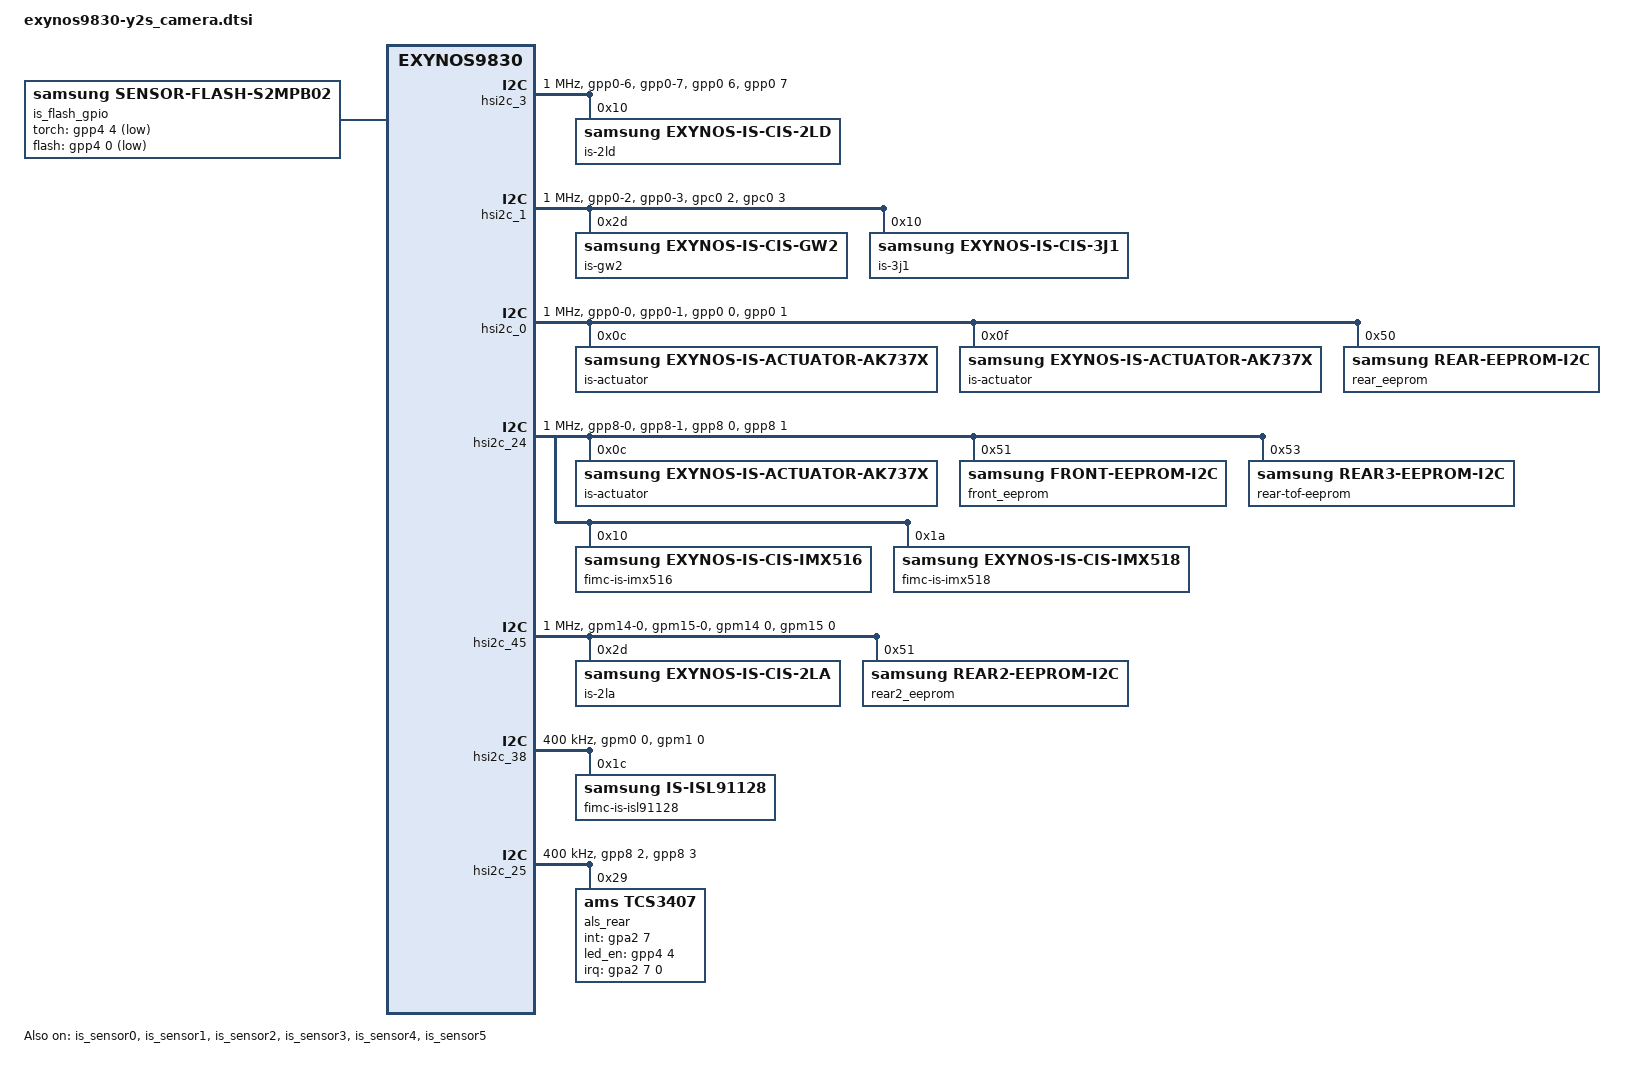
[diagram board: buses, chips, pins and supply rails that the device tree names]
/*
 * Samsung Exynos SoC series Pablo driver
 *
 * Copyright (c) 2019 Samsung Electronics Co., Ltd
 *
 * This program is free software; you can redistribute it and/or modify
 * it under the terms of the GNU General Public License version 2 as
 * published by the Free Software Foundation.
 */

#include <dt-bindings/camera/exynos_is_dt.h>
#include <dt-bindings/interrupt-controller/exynos9830.h>
#include <dt-bindings/clock/exynos9830.h>

#include "camera/module_2ld.dtsi"
#include "camera/module_3j1.dtsi"
#include "camera/module_2la.dtsi"
#include "camera/module_gw2.dtsi"
#include "camera/module_imx516.dtsi"
#include "camera/module_imx518.dtsi"

/ {
	fragment@camera {
		target-path = "/";
		__overlay__ {
			/* REAR CAMERA */
			is_sensor_2ld: is_sensor_2ld@20 {
				pinctrl-names = "pin0", "pin1", "pin2", "release";
				pinctrl-0 = <>;
				pinctrl-1 = <&sensor_mclk0_out>;
				pinctrl-2 = <&sensor_mclk0_fn>;
				pinctrl-3 = <>;

				/* board */
				position = <0>;	/* Rear:0. Front:1. Rear_sub:2. Secure:3. */
				id = <0>; /* is_sensor id */
				mclk_ch = <0>;
				sensor_i2c_ch = <0>; /* SENSOR_CONTROL_I2C0 */

				/* vendor */
				rom_type = <2>; /* ROM_TYPE_EEPROM */
				rom_id = <0>;
				rom_cal_index = <0>;

				/* peri */
				af {
					product_name = <18>; /* ACTUATOR_NAME_AK737X : ak7371 or ak7374 */
					i2c_ch = <2>; /* SENSOR_CONTROL_I2C2 */
				};

				flash {
					product_name = <11>; /* FLASH_GPIO */
				};

				mcu {
					product_name = <2>; /* INTERNAL */
				};

				vc_extra {
					/* ex) statX = <stat_type, sensor_mode, max_width, max_height, max_element> */
					stat0 = </* not avaliable */>;									/* VC_BUF_DATA_TYPE_SENSOR_STAT1 */
					stat1 = </*VC_STAT_TYPE_PDP_1_1_PDAF_STAT0*/ 800 /*VC_SENSOR_MODE_2PD_MODE3*/ 102 512 84 1>;	/* VC_BUF_DATA_TYPE_GENERAL_STAT1 */
					stat2 = </* not avaliable */>;									/* VC_BUF_DATA_TYPE_SENSOR_STAT2 */
					stat3 = </*VC_STAT_TYPE_PDP_1_1_PDAF_STAT1*/ 801 /*VC_SENSOR_MODE_2PD_MODE3*/ 102 512 84 1>;	/* VC_BUF_DATA_TYPE_GENERAL_STAT2 */
				};

				modes { 
					/* common = <width, height, fps, settle, mode, lane, speed, interleave, lrte, pd_mode> */
					/* vcX = <map, hwformat, width, height, hwformat, type, width, height> */
					/* CAMERA_2LD_SLOW_MOTION_PDAF_OFF */
					mode9 { /* SENSOR_2LD_2016X1134_240FPS */
						common = <2016 1134 240 0 9 CSI_DATA_LANES_3 2964 CSI_MODE_VC_DT LRTE_ENABLE PD_NONE>;
						vc1 = </* in */ 1 HW_FORMAT_UNKNOWN 0 0	/* out */ HW_FORMAT_UNKNOWN VC_NOTHING 0 0>;
					};
				};

				power_seq {
					use = <1>;
					gpio_mclk = <&gpc0 0 0x1>;

					scenario_normal_on {
						sensor_scenario = <SENSOR_SCENARIO_NORMAL>;
						gpio_scenario = <GPIO_SCENARIO_ON>;

						/* A start node number should be over the 10 for reserved number 0~9. */
						/* pname = "name"; pin = <act value delay voltage>; gpio = <gpx# # 0x1>; */
						5 { pname = "S2MPB02_BUCK2"; pin = <PIN_REGULATOR 1 0>; share = <SRT_ACQUIRE SHARED_PIN5 1>; };
						20 { pname = "VDDIO_1.8V_CAM"; pin = <PIN_REGULATOR 1 300>; share = <SRT_ACQUIRE SHARED_PIN2 1>; };
						60 { pname = "VDDAF_COMMON_CAM"; pin = <PIN_REGULATOR 1 1>; actuator_i2c_delay = <10000>; };
						85 { pname = "VDD_VM_2.8V_OIS"; pin = <PIN_REGULATOR 1 100>; share = <SRT_ACQUIRE SHARED_PIN3 1>; };
						86 { pname = "VDDD_1.8V_OIS"; pin = <PIN_REGULATOR 1 0>; share = <SRT_ACQUIRE SHARED_PIN4 1>; };
						100 { pname = "pin"; pin = <PIN_FUNCTION 2 0>; share = <SRT_ACQUIRE SHARED_PIN1 1>; };
						110 { pname = "MCLK"; pin = <PIN_MCLK 1 1500>; share = <SRT_ACQUIRE SHARED_PIN0 1>; };
					};

					scenario_vision_on {
					};

					scenario_hw_init_normal_on {
						/* HW INIT (without ois power control) */
					};

					scenario_normal_off {
						sensor_scenario = <SENSOR_SCENARIO_NORMAL>;
						gpio_scenario = <GPIO_SCENARIO_OFF>;

						/* A start node number should be over the 10 for reserved number 0~9. */
						/* pname = "name"; pin = <act value delay voltage>; gpio = <gpx# # 0x1>; */
						60 { pname = "MCLK"; pin = <PIN_MCLK 0 0>; share = <SRT_RELEASE SHARED_PIN0 0>; };
						80 { pname = "pin"; pin = <PIN_FUNCTION 1 0>; share = <SRT_RELEASE SHARED_PIN1 0>; };
						116 { pname = "VDDD_1.8V_OIS"; pin = <PIN_REGULATOR 0 0>; share = <SRT_RELEASE SHARED_PIN4 0>; };
						117 { pname = "VDD_VM_2.8V_OIS"; pin = <PIN_REGULATOR 0 0>; share = <SRT_RELEASE SHARED_PIN3 0>; };
						130 { pname = "VDDIO_1.8V_CAM"; pin = <PIN_REGULATOR 0 10>; share = <SRT_RELEASE SHARED_PIN2 0>; };
						140 { pname = "S2MPB02_BUCK2"; pin = <PIN_REGULATOR 0 0>; share = <SRT_RELEASE SHARED_PIN5 0>; };
					};

					scenario_vision_off {
					};

					scenario_retention_on {
						sensor_scenario = <SENSOR_SCENARIO_NORMAL>;
						gpio_scenario = <GPIO_SCENARIO_SENSOR_RETENTION_ON>;

						/* A start node number should be over the 10 for reserved number 0~9. */
						/* pname = "name"; pin = <act value delay voltage>; gpio = <gpx# # 0x1>; */
						20 { pname = "MCLK"; pin = <PIN_MCLK 0 0>; share = <SRT_RELEASE SHARED_PIN0 0>; };
						40 { pname = "pin"; pin = <PIN_FUNCTION 1 0>; share = <SRT_RELEASE SHARED_PIN1 0>; };
						116 { pname = "VDD_VM_2.8V_OIS"; pin = <PIN_REGULATOR 0 0>; share = <SRT_RELEASE SHARED_PIN3 0>; };
						117 { pname = "VDDD_1.8V_OIS"; pin = <PIN_REGULATOR 0 0>; share = <SRT_RELEASE SHARED_PIN4 0>; };
						140 { pname = "S2MPB02_BUCK2"; pin = <PIN_REGULATOR 0 0>; share = <SRT_RELEASE SHARED_PIN5 0>; };
					};

					scenario_hw_init_retention_on {
						/* RETENTION ON HW INIT(without ois power control) */
					};

					scenario_ois_factory_on {
					};

					scenario_ois_factory_off {
					};

					scenario_read_rom_on {
					};

					scenario_read_rom_off {
					};
				};
			};

			/* Tele CAMERA */
			is_sensor_gw2: is_sensor_gw2@5A {
				pinctrl-names = "pin0", "pin1", "pin2", "release";
				pinctrl-0 = <>;
				pinctrl-1 = <&sensor_mclk0_out>;
				pinctrl-2 = <&sensor_mclk0_fn>;
				pinctrl-3 = <>;

				/* board */
				position = <2>; /* Rear:0. Front:1, Tele:2 */
				id = <2>; /* is_sensor id */
				mclk_ch = <0>;
				sensor_i2c_ch = <1>; /* SENSOR_CONTROL_I2C1 */

				/* vendor */
				rom_type = <2>; /* ROM_TYPE_EEPROM */
				rom_id = <0>;
				rom_cal_index = <1>;
				rom_dualcal_id = <0>;
				rom_dualcal_index = <1>;

				af {
					product_name = <18>; /* ACTUATOR_NAME_AK737X : ak7371 or ak7374 */
					i2c_ch = <2>; /* SENSOR_CONTROL_I2C2 */
				};

				flash {
					product_name = <11>; /* FLASH_GPIO */
				};

				preprocessor {
					product_name = <100>; /* NOTHING */
				};

				mcu {
					product_name = <2>; /* INTERNAL */
				};

				vc_extra {
					/* ex) statX = <stat_type, sensor_mode, max_width, max_height, max_element> */
					stat0 = </* not avaliable */>;			/* VC_BUF_DATA_TYPE_SENSOR_STAT1 */
					stat1 = </*VC_STAT_TYPE_PDP_1_1_PDAF_STAT0*/ 800 /*VC_SENSOR_MODE_2PD_MODE3*/ 405 1160 1736 2>;		/* VC_BUF_DATA_TYPE_GENERAL_STAT1 */
					stat2 = </* not avaliable */>;			/* VC_BUF_DATA_TYPE_SENSOR_STAT2 */
					stat3 = </*VC_STAT_TYPE_PDP_1_1_PDAF_STAT1*/ 801 /*VC_SENSOR_MODE_2PD_MODE3*/ 405 1160 1736 2>;	/* VC_BUF_DATA_TYPE_GENERAL_STAT2 */
				};

				power_seq {
					use = <1>;
					gpio_mclk = <&gpc0 0 0x1>;

					scenario_normal_on {
						sensor_scenario = <SENSOR_SCENARIO_NORMAL>;
						gpio_scenario = <GPIO_SCENARIO_ON>;

						/* A start node number should be over the 10 for reserved number 0~9. */
						/* pname = "name"; pin = <act value delay voltage>; gpio = <gpx# # 0x1>; */
						30 { pname = "VDDAF_2.8V_SUB"; pin = <PIN_REGULATOR 1 2000>; actuator_i2c_delay = <10000>; };
						35 { pname = "VDD_VM_2.8V_OIS"; pin = <PIN_REGULATOR 1 100>; share = <SRT_ACQUIRE SHARED_PIN3 1>; };
						36 { pname = "VDDD_1.8V_OIS"; pin = <PIN_REGULATOR 1 0>; share = <SRT_ACQUIRE SHARED_PIN4 1>; };
						40 { pname = "VDDIO_1.8V_CAM"; pin = <PIN_REGULATOR 1 100>; share = <SRT_ACQUIRE SHARED_PIN2 1>; };
						45 { pname = "VDDIO_1.8V_VT"; pin = <PIN_REGULATOR 1 0>; share = <SRT_ACQUIRE SHARED_PIN6 1>; };
						70 { pname = "pin"; pin = <PIN_FUNCTION 2 0>; share = <SRT_ACQUIRE SHARED_PIN1 1>; };
						80 { pname = "MCLK"; pin = <PIN_MCLK 1 0>; share = <SRT_ACQUIRE SHARED_PIN0 1>; };
					};

					scenario_normal_off {
						sensor_scenario = <SENSOR_SCENARIO_NORMAL>;
						gpio_scenario = <GPIO_SCENARIO_OFF>;

						/* A start node number should be over the 10 for reserved number 0~9. */
						/* pname = "name"; pin = <act value delay voltage>; gpio = <gpx# # 0x1>; */
						40 { pname = "VDDIO_1.8V_CAM"; pin = <PIN_REGULATOR 0 0>; share = <SRT_RELEASE SHARED_PIN2 0>; };
						55 { pname = "VDDIO_1.8V_VT"; pin = <PIN_REGULATOR 0 0>; share = <SRT_RELEASE SHARED_PIN6 0>; };
						76 { pname = "VDDD_1.8V_OIS"; pin = <PIN_REGULATOR 0 0>; share = <SRT_RELEASE SHARED_PIN4 0>; };
						77 { pname = "VDD_VM_2.8V_OIS"; pin = <PIN_REGULATOR 0 0>; share = <SRT_RELEASE SHARED_PIN3 0>; };
						80 { pname = "MCLK"; pin = <PIN_MCLK 0 0>; share = <SRT_RELEASE SHARED_PIN0 0>; };
						100 { pname = "pin"; pin = <PIN_FUNCTION 1 0>; share = <SRT_RELEASE SHARED_PIN1 0>; };
					};

					scenario_vision_on {
					};

					scenario_vision_off {
					};
				};
			};

			/* Ultra Wide CAMERA */
			is_sensor_2la: is_sensor_2la@2D {
				pinctrl-names = "pin0", "pin1", "pin2", "release";
				pinctrl-0 = <>;
				pinctrl-1 = <&sensor_mclk4_out>;
				pinctrl-2 = <&sensor_mclk4_fn>;
				pinctrl-3 = <>;

				/* board */
				position = <4>; /* Rear:0. Front:1, Tele:2 */
				id = <4>; /* is_sensor id */
				mclk_ch = <3>;
				sensor_i2c_ch = <4>; /* SENSOR_CONTROL_I2C4 */

				/* vendor */
				rom_type = <2>; /* ROM_TYPE_EEPROM */
				rom_id = <2>;
				rom_cal_index = <0>;
				rom_dualcal_id = <0>;
				rom_dualcal_index = <0>;

				af {
					product_name = <100>; /* NOTHING */
				};

				flash {
					product_name = <11>; /* FLASH_GPIO */
				};

				preprocessor {
					product_name = <100>; /* NOTHING */
				};

				ois {
					product_name = <100>; /* NOTHING */
				};

				power_seq {
					use = <1>;
					gpio_mclk = <&gpc0 3 0x1>;

					scenario_normal_on {
						sensor_scenario = <SENSOR_SCENARIO_NORMAL>;
						gpio_scenario = <GPIO_SCENARIO_ON>;

						/* A start node number should be over the 10 for reserved number 0~9. */
						/* pname = "name"; pin = <act value delay voltage>; gpio = <gpx# # 0x1>; */
						5 { pname = "S2MPB02_BUCK2"; pin = <PIN_REGULATOR 1 0>; share = <SRT_ACQUIRE SHARED_PIN5 1>; };
					};

					scenario_normal_off {
						sensor_scenario = <SENSOR_SCENARIO_NORMAL>;
						gpio_scenario = <GPIO_SCENARIO_OFF>;

						/* A start node number should be over the 10 for reserved number 0~9. */
						/* pname = "name"; pin = <act value delay voltage>; gpio = <gpx# # 0x1>; */
						140 { pname = "S2MPB02_BUCK2"; pin = <PIN_REGULATOR 0 0>; share = <SRT_RELEASE SHARED_PIN5 0>; };
					};

					scenario_vision_on {
					};

					scenario_vision_off {
					};

					scenario_read_rom_on {
					};

					scenario_read_rom_off {
					};
				};
			};

			/* FRONT CAMERA */
			is_sensor_3j1: is_sensor_3j1@10 {
				pinctrl-names = "pin0", "pin1", "pin2", "release";
				pinctrl-0 = <>;
				pinctrl-1 = <&sensor_mclk2_out>;
				pinctrl-2 = <&sensor_mclk2_fn>;
				pinctrl-3 = <>;

				/* board */
				position = <1>;	/* Rear:0. Front:1. Rear_sub:2. Secure:3. */
				id = <1>; /* is_sensor id */
				mclk_ch = <1>;
				sensor_i2c_ch = <1>; /* SENSOR_CONTROL_I2C1 */

				/* vendor */
				rom_type = <2>; /* ROM_TYPE_EEPROM */
				rom_id = <1>;
				rom_cal_index = <0>;

				/* peri*/
				af {
					product_name = <18>; /* ACTUATOR_NAME_AK737X */
					i2c_ch = <3>; /* SENSOR_CONTROL_I2C3 */
				};

				flash {
					product_name = <100>; /* NOTHING */
				};

				ois {
					product_name = <100>; /* NOTHING */
				};

				vc_extra {
					/* ex) statX = <stat_type, sensor_mode, max_width, max_height, max_element> */
					stat0 = </* not avaliable */>;									/* VC_BUF_DATA_TYPE_SENSOR_STAT1 */
					stat1 = </*VC_STAT_TYPE_PDP_1_1_PDAF_STAT0*/ 800 /*VC_SENSOR_MODE_2PD_MODE3*/ 102 512 84 1>;	/* VC_BUF_DATA_TYPE_GENERAL_STAT1 */
					stat2 = </* not avaliable */>;									/* VC_BUF_DATA_TYPE_SENSOR_STAT2 */
					stat3 = </*VC_STAT_TYPE_PDP_1_1_PDAF_STAT1*/ 801 /*VC_SENSOR_MODE_2PD_MODE3*/ 102 512 84 1>;	/* VC_BUF_DATA_TYPE_GENERAL_STAT2 */
				};

				power_seq {
					use = <1>;
					gpio_mclk = <&gpc0 1 0x1>;

					scenario_normal_on {
						sensor_scenario = <SENSOR_SCENARIO_NORMAL>;
						gpio_scenario = <GPIO_SCENARIO_ON>;

						/* A start node number should be over the 10 for reserved number 0~9. */
						/* pname = "name"; pin = <act value delay voltage>; gpio = <gpx# # 0x1>; */
						5 { pname = "S2MPB02_BUCK2"; pin = <PIN_REGULATOR 1 0>; share = <SRT_ACQUIRE SHARED_PIN5 1>; };
						10 { pname = "VDDAF_2.8V_VT"; pin = <PIN_REGULATOR 1 0>; actuator_i2c_delay = <10000>; };
						70 { pname = "pin"; pin = <PIN_FUNCTION 2 0>; };
						80 { pname = "MCLK"; pin = <PIN_MCLK 1 9000>; };
					};

					scenario_normal_off {
						sensor_scenario = <SENSOR_SCENARIO_NORMAL>;
						gpio_scenario = <GPIO_SCENARIO_OFF>;

						/* A start node number should be over the 10 for reserved number 0~9. */
						/* pname = "name"; pin = <act value delay voltage>; gpio = <gpx# # 0x1>; */
						10 { pname = "MCLK"; pin = <PIN_MCLK 0 1>; };
						30 { pname = "pin"; pin = <PIN_FUNCTION 1 0>; };
						140 { pname = "S2MPB02_BUCK2"; pin = <PIN_REGULATOR 0 0>; share = <SRT_RELEASE SHARED_PIN5 0>; };
					};

					scenario_vision_on {
					};

					scenario_vision_off {
					};
				};
			};

			/* REAR TOF */
			is_sensor_imx516: is_sensor_imx516@10 {
				pinctrl-names = "pin0", "pin1", "pin2", "release";
				pinctrl-0 = <>;
				pinctrl-1 = <&sensor_mclk3_out>;
				pinctrl-2 = <&sensor_mclk3_fn>;
				pinctrl-3 = <>;

				position = <8>; /* Rear:0. Front:1, Tele:2 */
				id = <3>; /* fimc_is_sensor id */
				mclk_ch = <2>;
				sensor_i2c_ch = <3>; /* SENSOR_CONTROL_I2C3 */

				rom_type = <2>; /* ROM_TYPE_EEPROM */
				rom_id = <4>;
				rom_cal_index = <0>;
				rom_dualcal_id = <0>;
				rom_dualcal_index = <2>;

				af {
					product_name = <100>;  /* NOTHING */
				};

				flash {
					product_name = <100>;  /* NOTHING */
				};

				preprocessor {
					product_name = <100>; /* NOTHING */
				};

				ois {
					product_name = <100>; /* NOTHING */
				};

				power_seq {
					use = <1>;
					gpio_mclk = <&gpc0 2 0x1>;

					scenario_normal_on {
						sensor_scenario = <SENSOR_SCENARIO_VISION>;
						gpio_scenario = <GPIO_SCENARIO_ON>;

						/* A start node number should be over the 10 for reserved number 0~9. */
						/* pname = "name"; pin = <act value dealy voltage>; gpio = <gpx# # 0x1>; */
						5 { pname = "S2MPB02_BUCK2"; pin = <PIN_REGULATOR 1 0>; share = <SRT_ACQUIRE SHARED_PIN5 1>; };
						45 { pname = "VDDIO_1.8V_VT"; pin = <PIN_REGULATOR 1 0>; share = <SRT_ACQUIRE SHARED_PIN6 1>; };
					};

					scenario_normal_off {
						sensor_scenario = <SENSOR_SCENARIO_VISION>;
						gpio_scenario = <GPIO_SCENARIO_OFF>;

						/* A start node number should be over the 10 for reserved number 0~9. */
						/* pname = "name"; pin = <act value dealy voltage>; gpio = <gpx# # 0x1>; */
						15 { pname = "VDDIO_1.8V_VT"; pin = <PIN_REGULATOR 0 0>; share = <SRT_RELEASE SHARED_PIN6 0>; };
						140 { pname = "S2MPB02_BUCK2"; pin = <PIN_REGULATOR 0 0>; share = <SRT_RELEASE SHARED_PIN5 0>; };
					};

					scenario_read_rom_on {
						sensor_scenario = <SENSOR_SCENARIO_READ_ROM>;
						gpio_scenario = <GPIO_SCENARIO_ON>;

						/* A start node number should be over the 10 for reserved number 0~9. */
						/* pname = "name"; pin = <act value dealy voltage>; gpio = <gpx# # 0x1>; */
						15 { pname = "VDDIO_1.8V_VT"; pin = <PIN_REGULATOR 1 0>; share = <SRT_ACQUIRE SHARED_PIN6 1>; };
					};

					scenario_read_rom_off {
						sensor_scenario = <SENSOR_SCENARIO_READ_ROM>;
						gpio_scenario = <GPIO_SCENARIO_OFF>;

						/* A start node number should be over the 10 for reserved number 0~9. */
						/* pname = "name"; pin = <act value dealy voltage>; gpio = <gpx# # 0x1>; */
						15 { pname = "VDDIO_1.8V_VT"; pin = <PIN_REGULATOR 0 0>; share = <SRT_RELEASE SHARED_PIN6 0>; };
					};
				};
			};

			is_sensor_imx518: is_sensor_imx518@1A {
				pinctrl-names = "pin0", "pin1", "pin2", "release";
				pinctrl-0 = <>;
				pinctrl-1 = <&sensor_mclk3_out>;
				pinctrl-2 = <&sensor_mclk3_fn>;
				pinctrl-3 = <>;

				position = <8>; /* Rear:0. Front:1, Tele:2 */
				id = <3>; /* fimc_is_sensor id */
				mclk_ch = <2>;
				sensor_i2c_ch = <3>; /* SENSOR_CONTROL_I2C3 */

				rom_type = <2>; /* ROM_TYPE_EEPROM */
				rom_id = <4>;
				rom_cal_index = <0>;
				rom_dualcal_id = <0>;
				rom_dualcal_index = <2>;

				af {
					product_name = <100>;  /* NOTHING */
				};

				flash {
					product_name = <100>;  /* NOTHING */
				};

				preprocessor {
					product_name = <100>; /* NOTHING */
				};

				ois {
					product_name = <100>; /* NOTHING */
				};

				power_seq {
					use = <1>;
					gpio_mclk = <&gpc0 2 0x1>;

					scenario_normal_on {
						sensor_scenario = <SENSOR_SCENARIO_VISION>;
						gpio_scenario = <GPIO_SCENARIO_ON>;

						/* A start node number should be over the 10 for reserved number 0~9. */
						/* pname = "name"; pin = <act value dealy voltage>; gpio = <gpx# # 0x1>; */
						5 { pname = "S2MPB02_BUCK2"; pin = <PIN_REGULATOR 1 0>; share = <SRT_ACQUIRE SHARED_PIN5 1>; };
						45 { pname = "VDDIO_1.8V_VT"; pin = <PIN_REGULATOR 1 0>; share = <SRT_ACQUIRE SHARED_PIN6 1>; };
					};

					scenario_normal_off {
						sensor_scenario = <SENSOR_SCENARIO_VISION>;
						gpio_scenario = <GPIO_SCENARIO_OFF>;

						/* A start node number should be over the 10 for reserved number 0~9. */
						/* pname = "name"; pin = <act value dealy voltage>; gpio = <gpx# # 0x1>; */
						15 { pname = "VDDIO_1.8V_VT"; pin = <PIN_REGULATOR 0 0>; share = <SRT_RELEASE SHARED_PIN6 0>; };
						140 { pname = "S2MPB02_BUCK2"; pin = <PIN_REGULATOR 0 0>; share = <SRT_RELEASE SHARED_PIN5 0>; };
					};

					scenario_read_rom_on {
						sensor_scenario = <SENSOR_SCENARIO_READ_ROM>;
						gpio_scenario = <GPIO_SCENARIO_ON>;

						/* A start node number should be over the 10 for reserved number 0~9. */
						/* pname = "name"; pin = <act value dealy voltage>; gpio = <gpx# # 0x1>; */
						15 { pname = "VDDIO_1.8V_VT"; pin = <PIN_REGULATOR 1 0>; share = <SRT_ACQUIRE SHARED_PIN6 1>; };
					};

					scenario_read_rom_off {
						sensor_scenario = <SENSOR_SCENARIO_READ_ROM>;
						gpio_scenario = <GPIO_SCENARIO_OFF>;

						/* A start node number should be over the 10 for reserved number 0~9. */
						/* pname = "name"; pin = <act value dealy voltage>; gpio = <gpx# # 0x1>; */
						15 { pname = "VDDIO_1.8V_VT"; pin = <PIN_REGULATOR 0 0>; share = <SRT_RELEASE SHARED_PIN6 0>; };
					};
				};
			};

			is_flash_gpio: is-flash-gpio@0 {
				compatible = "samsung,sensor-flash-s2mpb02";
				id = <0 2 4>;
				status = "okay";

				torch-gpio = <&gpp4 4 0x1>;
				flash-gpio = <&gpp4 0 0x1>;
			};
		}; /* end of __overlay__ */
	}; /* end of fragment */
}; /* end of root */

/***** reference symbol node *****/
&pinctrl_0 {
	tof_reset_sleep: tof-reset-sleep {
		samsung,pins = "gpa3-3";
		samsung,pin-function = <0>;
	};
};

&pinctrl_1 {
	sensor_reset_sleep: sensor-reset-sleep {
		samsung,pins = "gpm11-0","gpm32-0","gpm33-0";
		samsung,pin-function = <0>;
	};

	/* U WIDE */
	hsi2c45_bus_in: hsi2c45-bus-in {
		samsung,pins = "gpm14-0", "gpm15-0";
		samsung,pin-function = <0>;
		samsung,pin-pud = <0>;
		samsung,pin-drv = <0>;
		samsung,pin-con-pdn = <2>;
		samsung,pin-pud-pdn = <0>;
	};

	hsi2c45_bus_sleep: hsi2c45-bus-sleep {
		samsung,pins = "gpm14-0", "gpm15-0";
		samsung,pin-pud = <1>;
	};
};

&pinctrl_4 {
	/* REAR AF, EEPROM */
	hsi2c0_bus_in: hsi2c0-bus-in {
		samsung,pins = "gpp0-0", "gpp0-1";
		samsung,pin-function = <0>;
		samsung,pin-pud = <0>;
		samsung,pin-drv = <0>;
		samsung,pin-con-pdn = <2>;
		samsung,pin-pud-pdn = <0>;
	};

	/* REAR TELE, FRONT */
	hsi2c1_bus_in: hsi2c1-bus-in {
		samsung,pins = "gpp0-2", "gpp0-3";
		samsung,pin-function = <0>;
		samsung,pin-pud = <0>;
		samsung,pin-drv = <0>;
		samsung,pin-con-pdn = <2>;
		samsung,pin-pud-pdn = <1>;
	};

	/* REAR WIDE */
	hsi2c3_bus_in: hsi2c3-bus-in {
		samsung,pins = "gpp0-6", "gpp0-7";
		samsung,pin-function = <0>;
		samsung,pin-pud = <0>;
		samsung,pin-drv = <0>;
		samsung,pin-con-pdn = <2>;
		samsung,pin-pud-pdn = <0>;
	};

	flash_init: flash-init {
		samsung,pins = "gpp4-0";
		samsung,pin-con-pdn = <0>;
	};

	torch_init: torch-init {
		samsung,pins = "gpp4-4";
		samsung,pin-con-pdn = <3>;
	};
};

&pinctrl_5 {
	/* FRONT AF, EEPROM */
	hsi2c24_bus_in: hsi2c24-bus-in {
		samsung,pins = "gpp8-0", "gpp8-1";
		samsung,pin-function = <0>;
		samsung,pin-pud = <0>;
		samsung,pin-drv = <0>;
		samsung,pin-con-pdn = <2>;
		samsung,pin-pud-pdn = <1>;
	};
};

&hsi2c_3 {
	#address-cells = <1>;
	#size-cells = <0>;
	gpios = <&gpp0 6 0 &gpp0 7 0>;
	status = "okay";
	clock-frequency = <1000000>;
	samsung,reset-before-trans;
	samsung,fast-plus-mode;

	pinctrl-names = "default","on_i2c","off_i2c";
	pinctrl-0 = <&hsi2c3_bus_in>;
	pinctrl-1 = <&hsi2c3_bus>;
	pinctrl-2 = <&hsi2c3_bus_in>;

	is-2ld@10 {
		compatible = "samsung,exynos-is-cis-2ld";
		reg = <0x10>; /* 1 bit right shift */
		id = <0>; /* matching is_sensor id */
		setfile = "default";
		rev_reg = <0x0002 2 0xA301>;
	};
};

&hsi2c_1 {
	#address-cells = <1>;
	#size-cells = <0>;
	gpios = <&gpc0 2 0 &gpc0 3 0>;
	status = "okay";
	clock-frequency = <1000000>;
	samsung,reset-before-trans;
	samsung,fast-plus-mode;

	pinctrl-names = "default","on_i2c","off_i2c";
	pinctrl-0 = <&hsi2c1_bus_in>;
	pinctrl-1 = <&hsi2c1_bus>;
	pinctrl-2 = <&hsi2c1_bus_in>;

	is-gw2@2D {
		compatible = "samsung,exynos-is-cis-gw2";
		reg = <0x2D>; /* 1 bit right shift */
		id = <2>; /* matching is_sensor id */
		setfile = "setA";
		rev_reg = <0x0002 2 0xA300>;
	};

	is-3j1@10 {
		compatible = "samsung,exynos-is-cis-3j1";
		reg = <0x10>; /* 1 bit right shift */
		id = <1>; /* matching is_sensor id */
		setfile = "default";
		rev_reg = <0x0002 1 0xA2>;
	};
};

&hsi2c_0 {
	#address-cells = <1>;
	#size-cells = <0>;
	gpios = <&gpp0 0 0 &gpp0 1 0>;
	status = "okay";
	clock-frequency = <1000000>;
	samsung,reset-before-trans;
	samsung,fast-plus-mode;

	pinctrl-names = "default","on_i2c","off_i2c";
	pinctrl-0 = <&hsi2c0_bus_in>;
	pinctrl-1 = <&hsi2c0_bus>;
	pinctrl-2 = <&hsi2c0_bus_in>;

	is-actuator@0C { /* wide AF */
		compatible = "samsung,exynos-is-actuator-ak737x";
		reg = <0x0C>;
		id = <0>; /* matching is_sensor id */
		/* AK737x: addr 0xF3, data 0x0E */
		vendor_product_id = <0xF3 0x0E 0xF3 0x13 0xF3 0x00>;
		vendor_first_pos = <250>;
		vendor_first_delay = <2000>;
		vendor_soft_landing_seqid = <1>;
		vendor_soft_landing_list = <100 30 0 30>; /* 1st_pos delay 2nd_pos delay */
		vendor_use_sleep_mode;
		vendor_use_standby_mode; /* AK7377 with vendor_use_sleep_mode */
	};

	is-actuator@0F { /* tele AF */
		compatible = "samsung,exynos-is-actuator-ak737x";
		reg = <0x0F>;
		id = <2>; /* matching sensor id */
		/* AK7377: addr 0xF3, data 0x0E */
		vendor_product_id = <0xF3 0x0E 0xF3 0x13 0xF3 0x00>;
		vendor_first_pos = <250>;
		vendor_first_delay = <2000>;
		vendor_soft_landing_seqid = <1>;
		vendor_soft_landing_list = <100 30 0 30>; /* 1st_pos delay 2nd_pos delay */
		vendor_use_sleep_mode;
		vendor_use_standby_mode; /* AK7377 with vendor_use_sleep_mode */
	};

	rear_eeprom@50 {
		compatible = "samsung,rear-eeprom-i2c";
		reg = <0x50>;
		rom_power_position = <0>;
		rom_size = <0x10000>;
		cal_map_es_version = <15>; // 15
		camera_module_es_version = "A";
		/* skip_cal_loading; */
		/* HubbleXY_Rear_Cal_Map_V015_20190828_for_LSI */
		/* 0 header */
		header_crc_check_list = <0x0000 0x01FB 0x01FC>;
		/* 0 master LSC */
		/* 1 master all */
		crc_check_list = <0x0200 0x1BFB 0x1BFC 0x1C00 0x35DF 0x35FC>;
		/* 0 u-wide dual cal data */
		/* 1 tele LSC */
		/* 2 tele dual cal data */
		dual_crc_check_list = <0x4000 0x59FB 0x59FC
					0x72F0 0x7AFB 0x7AFC>;
		/* Master */
		rom_header_version_start_addr = <0x50>;
		rom_header_cal_data_start_addr = <0x200>;
		rom_header_cal_map_ver_start_addr = <0x70>;
		rom_header_isp_setfile_ver_start_addr = <0x74>;
		rom_header_project_name_start_addr = <0x7E>;
		rom_header_module_id_addr = <0xAE>; /* 0xA8 + reserved bytes */
		rom_header_sensor_id_addr = <0xB8>;
		rom_header_mtf_data_addr = <0xE0>;
		rom_awb_master_addr = <0x3440>;
		rom_awb_module_addr = <0x3464>;
		rom_af_cal_d10_addr = <0x3420>;
		rom_af_cal_d50_addr = <0x3418>;
		rom_af_cal_pan_addr = <0x3414>;
		/* Slave 0 */
		rom_header_sensor2_version_start_addr = <0x40>;
		rom_header_sensor2_id_addr = <0xC8>;
		rom_header_sensor2_mtf_data_addr = <0x182>;
		rom_sensor2_awb_master_addr = <0x7240>;
		rom_sensor2_awb_module_addr = <0x7264>;
		rom_sensor2_af_cal_d30_addr = <0x7220>;
		rom_sensor2_af_cal_d50_addr = <0x7218>;
		rom_sensor2_af_cal_pan_addr = <0x7214>;
		/* Dual cal slave 0 - Ultra wide */
		rom_dualcal_slave0_start_addr = <0x3600>;
		rom_dualcal_slave0_size = <0x08FC>; /* 2300 */
		/* x y z sx sy */
		/* range max_err avg_err dll_version prj_name */
		rom_dualcal_slave0_tilt_list = <0x3660 0x3664 0x3668 0x36C0 0x36C4
						0x3DE0 0x3DE4 0x3DE8 0x3600 0x3D42>;
		/* Dual cal slave 1 - Tele */
		rom_dualcal_slave1_start_addr = <0x72F0>;
		rom_dualcal_slave1_size = <0x080C>; /* 2060 */
		/* x y z sx sy */
		/* range max_err avg_err dll_version prj_name */
		rom_dualcal_slave1_tilt_list = <0x73A8 0x73AC 0x73B0 0x73CC 0x73D0
						0x75C2 0x75C6 0x75CA 0x75E4 0x75CF>;

		rom_dualcal_slave1_cropshift_x_addr= <0x758E>;
		rom_dualcal_slave1_cropshift_y_addr= <0x7590>;

		rom_dualcal_slave1_dummy_flag_addr= <0x75E3>;

		/* sensor ois - xgg ygg xcoef ycoef xsupper ysupper calmark */
		/* sensor2 ois - xgg ygg xcoef ycoef xsupper ysupper calmark */
		/* TO DO */
		rom_ois_list = <0x34F0 0x34F4 0x34FC 0x34FE 0x3518 0x351A 0x3510
				0x7B10 0x7B14 0x7B1C 0x7B1E 0x7B38 0x7B3A 0x7B30>;

		/* Tele Crostalk Cal data */
		rom_pdxtc_cal_data_start_addr = <0x7E04>;
		rom_pdxtc_cal_data_0_size = <6>;
		rom_pdxtc_cal_data_1_size = <540>;

		/* Dual cal slave 2 - TOF */
		rom_dualcal_slave2_start_addr = <0x8300>;
		rom_dualcal_slave2_size = <0x8FC>; /* 2300 */

		/* Dual cal slave 2 - wide - TOF tilt */
		/* x y z sx sy */
		/* range max_err avg_err dll_version*/
		rom_dualcal_slave2_tilt_list = <0x836C 0x8370 0x8374 0x86C0 0x86C4
										0x87E0 0x87E4 0x87E8 0x8300>;
		/* Dual cal slave 3 - ultra wide - TOF tilt */
		/* x y z sx sy */
		/* range max_err avg_err dll_version*/
		rom_dualcal_slave3_tilt_list = <0x8460 0x8464 0x8468 0x88C8 0x88CC
										0x89E8 0x89EC 0x89F0 0x8300>;
	};
};

&hsi2c_24 {
	#address-cells = <1>;
	#size-cells = <0>;
	gpios = <&gpp8 0 0 &gpp8 1 0>;
	status = "okay";
	clock-frequency = <1000000>;
	samsung,reset-before-trans;
	samsung,fast-plus-mode;

	pinctrl-names = "default","on_i2c","off_i2c";
	pinctrl-0 = <&hsi2c24_bus_in>;
	pinctrl-1 = <&hsi2c24_bus>;
	pinctrl-2 = <&hsi2c24_bus_in>;

	is-actuator@0C { /* front AF */
		compatible = "samsung,exynos-is-actuator-ak737x";
		reg = <0x0C>;
		id = <1>; /* matching is_sensor id */
		/* AK737x: addr 0xF3, data 0x0E */
		vendor_product_id = <0xF3 0x0E>;
		vendor_first_pos = <120>;
		vendor_first_delay = <2000>;
	};

	front_eeprom@51 {
		compatible = "samsung,front-eeprom-i2c";
		reg = <0x51>;
		rom_power_position = <1>;
		rom_size = <0x4000>;
		cal_map_es_version = <4>; //6
		camera_module_es_version = "A";
		/*skip_cal_loading;*/
		/* HubbleXY_Front_Cal_Map_V006_20190723_for_LSI */
		/* 0 header */
		header_crc_check_list = <0x0000 0x015F 0x01FC>;
		/* 0 master */
		crc_check_list = <0x0200 0x34DF 0x34FC>;
		/* Master */
		rom_header_version_start_addr = <0x30>;
		rom_header_cal_data_start_addr = <0x200>;
		rom_header_cal_map_ver_start_addr = <0x50>;
		/* rom_header_isp_setfile_ver_start_addr = <>; */
		rom_header_project_name_start_addr = <0x5C>;
		rom_header_module_id_addr = <0xAE>; /* 0xA8 + reserved bytes */
		rom_header_sensor_id_addr = <0x70>;
		rom_header_mtf_data_addr = <0xE0>;
		rom_awb_master_addr = <0x1A40>;
		rom_awb_module_addr = <0x1A4C>;
		rom_af_cal_d10_addr = <0x1A20>;
		rom_af_cal_pan_addr = <0x1A14>;
	};

	rear-tof-eeprom@53 {
		compatible = "samsung,rear3-eeprom-i2c";
		reg = <0x53>;

		rom_power_position = <8>;
		rom_size = <0x1900>;
		cal_map_es_version = <1>; /* TO DO 1 -> 2 */
		camera_module_es_version = "A";
		/* skip_header_loading; */
		/* skip_crc_check; */
		/*skip_cal_loading;*/

		/* piccaso_REAR_TOF_Cal_Map_V001_190725 */
		/* 0 header */
		header_crc_check_list = <0x0000 0x00C9 0x00FC>;
		/* 1 cal all */
		crc_check_list = <0x0100 0x128F 0x18FC>;

		rom_header_cal_map_ver_start_addr = <0x50>;
		rom_header_version_start_addr = <0x40>;

		rom_header_module_id_addr = <0xAE>;
		rom_header_sensor_id_addr = <0xB8>;

		rom_tof_cal_size_addr = <0x0142>; /* QVGA CAL */
		rom_tof_cal_start_addr = <0x0100>;
		rom_tof_cal_mode_id_addr = <0x11A4>;  /* VGA UID */
		rom_tof_cal_result_addr = <0x00CA>;
		rom_tof_cal_validation_addr = <0x11D0 0x11EE>; /*QVGA 500 start, 300 start*/
	};

	fimc-is-imx516@10 { /* rear tof */
		compatible = "samsung,exynos-is-cis-imx516";
		reg = <0x10>; /* 1 bit right shift */
		id = <3>; /* matching fimc_is_sensor id */
		setfile = "setA";
		status = "okay";
	};

	fimc-is-imx518@1A { /* rear tof */
		compatible = "samsung,exynos-is-cis-imx518";
		reg = <0x1A>; /* 1 bit right shift */
		id = <3>; /* matching fimc_is_sensor id */
		setfile = "setA";
		status = "okay";
	};
};

&hsi2c_45 {
	#address-cells = <1>;
	#size-cells = <0>;
	gpios = <&gpm14 0 0 &gpm15 0 0>;
	status = "okay";
	clock-frequency = <1000000>;
	samsung,reset-before-trans;
	samsung,fast-plus-mode;

	pinctrl-names = "default","on_i2c","off_i2c";
	pinctrl-0 = <&hsi2c45_bus_in>;
	pinctrl-1 = <&hsi2c45_bus>;
	pinctrl-2 = <&hsi2c45_bus_in>;

	is-2la@2D {
		compatible = "samsung,exynos-is-cis-2la";
		reg = <0x2D>; /* 1 bit right shift */
		id = <4>; /* matching is_sensor id */
		setfile = "setA";
		status = "okay";
		rev_reg = <0x0002 2 0xA202>;
	};

	rear2_eeprom@51 { /* Ultra wide eeprom */
		compatible = "samsung,rear2-eeprom-i2c";
		reg = <0x51>;

		rom_power_position = <4>;
		rom_size = <0x4000>;
		cal_map_es_version = <15>;
		camera_module_es_version = "A";
		/*skip_cal_loading;*/

		/* HubbleXY_Rear_Cal_Map_V015_20190828_for_LSI */
		/* 0 header */
		header_crc_check_list = <0x0000 0x00FB 0x00FC>;
		/* 0 master LSC */
		/* 1 master all */
		crc_check_list = <0x0100 0x1AFB 0x1AFC 0x2200 0x22DF 0x22FC>;

		/* Master */
		rom_header_version_start_addr = <0x40>;
		rom_header_cal_data_start_addr = <0x100>;
		rom_header_cal_map_ver_start_addr = <0x50>;
		rom_header_isp_setfile_ver_start_addr = <0x54>;
		rom_header_project_name_start_addr = <0x5E>;
		rom_header_module_id_addr = <0xAE>; /* 0xA8 + reserved bytes */
		rom_header_sensor_id_addr = <0xB8>;
		rom_header_mtf_data_addr = <0x66>;
		rom_awb_master_addr = <0x2200>;
		rom_awb_module_addr = <0x2224>;
	};
};

/* isl91128 */
&hsi2c_38 {
	#address-cells = <1>;
	#size-cells = <0>;
	gpios = <&gpm0 0 0 &gpm1 0 0>;
	status = "okay";
	clock-frequency = <400000>;
	samsung,reset-before-trans;

	pinctrl-names = "default","on_i2c","off_i2c";
	pinctrl-0 = <&hsi2c38_bus>;
	pinctrl-1 = <&hsi2c38_bus>;
	pinctrl-2 = <&hsi2c38_bus>;

	fimc-is-isl91128@1C { /* RTOF POWER */
		compatible = "samsung,is-isl91128";
		reg = <0x1C>; /* 1 bit right shift */
		voltage_option = <1>; /* 1 : ouput level is 3.35V */
	};
};

/* REAR CAMERA */
&is_sensor0 {
	#address-cells = <1>;
	#size-cells = <1>;
	scenario = <SENSOR_SCENARIO_NORMAL>;	/* Normal, Vision, OIS etc */
	id = <0>;
	csi_ch = <0>;
	dma_ch = <2 2 2 2
		0 0 0 0>;
	vc_ch = <0 1 2 3
		0 1 2 3>;
	flite_ch = <FLITE_ID_NOTHING>;
	is_bns = <0>;
	status = "okay";
	use_cphy = <1>;

	interrupts = <0 INTREQ__CSIS0 IRQ_TYPE_LEVEL_HIGH>, /*MIPI-CSI0 */
		<0 INTREQ__CSIS_DMA2 IRQ_TYPE_LEVEL_HIGH>,
		<0 INTREQ__CSIS_DMA2 IRQ_TYPE_LEVEL_HIGH>,
		<0 INTREQ__CSIS_DMA2 IRQ_TYPE_LEVEL_HIGH>,
		<0 INTREQ__CSIS_DMA2 IRQ_TYPE_LEVEL_HIGH>,
		<0 INTREQ__CSIS_DMA0 IRQ_TYPE_LEVEL_HIGH>,
		<0 INTREQ__CSIS_DMA0 IRQ_TYPE_LEVEL_HIGH>,
		<0 INTREQ__CSIS_DMA0 IRQ_TYPE_LEVEL_HIGH>,
		<0 INTREQ__CSIS_DMA0 IRQ_TYPE_LEVEL_HIGH>;
	interrupt-names = "csi",
		"mode0_VC0", "mode0_VC1","mode0_VC2","mode0_VC3",
		"mode1_VC0", "mode1_VC1","mode1_VC2","mode1_VC3";

	/* without frame ID decoder */
	sensor0_ch_mode0: sensor0-ch-mode0 {
		reg = <0x170C3000 0x100>, /* DMA2 VC0 */
			<0x170C3400 0x100>, /* DMA2 Common */
			<0x170C3100 0x100>, /* DMA2 VC1 */
			<0x170C3400 0x100>, /* DMA2 Common */
			<0x170C3200 0x100>, /* DMA2 VC2 */
			<0x170C3400 0x100>, /* DMA2 Common */
			<0x170C3300 0x100>, /* DMA2 VC3 */
			<0x170C3400 0x100>; /* DMA2 Common */
		mux_reg = <0x1702041C 0x4>; /* DMA2 input mux */
	};

	/* with frame ID decoder */
	sensor0_ch_mode1: sensor0-ch-mode1 {
		reg = <0x170C1000 0x100>, /* DMA0 VC0 */
			<0x170C1400 0x100>, /* DMA0 Common */
			<0x170C1100 0x100>, /* DMA0 VC1 */
			<0x170C1400 0x100>, /* DMA0 Common */
			<0x170C1200 0x100>, /* DMA0 VC2 */
			<0x170C1400 0x100>, /* DMA0 Common */
			<0x170C1300 0x100>, /* DMA0 VC3 */
			<0x170C1400 0x100>; /* DMA0 Common */
		mux_reg = <0x17020414 0x4>; /* DMA0 input mux */
	};
};

/* FRONT CAMERA */
&is_sensor1 {
	#address-cells = <1>;
	#size-cells = <1>;
	scenario = <SENSOR_SCENARIO_NORMAL>;    /* Normal, Vision, OIS etc */
	id = <1>;
	csi_ch = <1>;
	dma_ch = <1 1 1 1
		1 1 1 1>;
	vc_ch = <0 1 2 3
		0 1 2 3>;
	flite_ch = <FLITE_ID_NOTHING>;
	is_bns = <0>;
	status = "okay";

	interrupts = <0 INTREQ__CSIS1 IRQ_TYPE_LEVEL_HIGH>, /* MIPI-CSI1 */
		<0 INTREQ__CSIS_DMA1 IRQ_TYPE_LEVEL_HIGH>,
		<0 INTREQ__CSIS_DMA1 IRQ_TYPE_LEVEL_HIGH>,
		<0 INTREQ__CSIS_DMA1 IRQ_TYPE_LEVEL_HIGH>,
		<0 INTREQ__CSIS_DMA1 IRQ_TYPE_LEVEL_HIGH>,
		<0 INTREQ__CSIS_DMA1 IRQ_TYPE_LEVEL_HIGH>,
		<0 INTREQ__CSIS_DMA1 IRQ_TYPE_LEVEL_HIGH>,
		<0 INTREQ__CSIS_DMA1 IRQ_TYPE_LEVEL_HIGH>,
		<0 INTREQ__CSIS_DMA1 IRQ_TYPE_LEVEL_HIGH>;
	interrupt-names = "csi",
		"mode0_VC0", "mode0_VC1","mode0_VC2","mode0_VC3",
		"mode1_VC0", "mode1_VC1","mode1_VC2","mode1_VC3";

	/* without PAF HW */
	sensor1_ch_mode0: sensor1-ch-mode0 {
		reg = <0x170C2000 0x100>, /* DMA1 VC0 */
			<0x170C2400 0x100>, /* DMA1 Common */
			<0x170C2100 0x100>, /* DMA1 VC1 */
			<0x170C2400 0x100>, /* DMA1 Common */
			<0x170C2200 0x100>, /* DMA1 VC2 */
			<0x170C2400 0x100>, /* DMA1 Common */
			<0x170C2300 0x100>, /* DMA1 VC3 */
			<0x170C2400 0x100>; /* DMA1 Common */
		mux_reg = <0x17020418 0x4>; /* DMA1 input mux */
	};

	/* with PAF HW */
	sensor1_ch_mode1: sensor1-ch-mode1 {
		reg = <0x170C2000 0x100>, /* DMA1 VC0 */
			<0x170C2400 0x100>, /* DMA1 Common */
			<0x170C2100 0x100>, /* DMA1 VC1 */
			<0x170C2400 0x100>, /* DMA1 Common */
			<0x170C2200 0x100>, /* DMA1 VC2 */
			<0x170C2400 0x100>, /* DMA1 Common */
			<0x170C2300 0x100>, /* DMA1 VC3 */
			<0x170C2400 0x100>; /* DMA1 Common */
		mux_reg = <0x17020418 0x4>; /* DMA1 input mux */
	};
};

/* Tele CAMERA */
&is_sensor2 {
	#address-cells = <1>;
	#size-cells = <1>;
	scenario = <SENSOR_SCENARIO_NORMAL>;    /* Normal, Vision, OIS etc */
	id = <2>;
	csi_ch = <2>;
	dma_ch = <3 3 3 3
		3 3 3 3>;
	vc_ch = <0 1 2 3
		0 1 2 3>;
	flite_ch = <FLITE_ID_NOTHING>;
	is_bns = <0>;
	status = "okay";
	use_cphy = <1>;

	reg = <0x0 0x17050000 0x1000>, /* MIPI-CSI2 */
		<0x0 0x170D0000 0x10000>; /* PHY: M0S4S4S4S4S4S2 */
	reg-names = "csi", "phy";

	interrupts = <0 INTREQ__CSIS2 IRQ_TYPE_LEVEL_HIGH>, /* MIPI-CSI2 */
		<0 INTREQ__CSIS_DMA3 IRQ_TYPE_LEVEL_HIGH>,
		<0 INTREQ__CSIS_DMA3 IRQ_TYPE_LEVEL_HIGH>,
		<0 INTREQ__CSIS_DMA3 IRQ_TYPE_LEVEL_HIGH>,
		<0 INTREQ__CSIS_DMA3 IRQ_TYPE_LEVEL_HIGH>,
		<0 INTREQ__CSIS_DMA3 IRQ_TYPE_LEVEL_HIGH>,
		<0 INTREQ__CSIS_DMA3 IRQ_TYPE_LEVEL_HIGH>,
		<0 INTREQ__CSIS_DMA3 IRQ_TYPE_LEVEL_HIGH>,
		<0 INTREQ__CSIS_DMA3 IRQ_TYPE_LEVEL_HIGH>;
	interrupt-names = "csi",
		"mode0_VC0", "mode0_VC1","mode0_VC2","mode0_VC3",
		"mode1_VC0", "mode1_VC1","mode1_VC2","mode1_VC3";

	phys = <&mipi_phy_csis2_m0s4s4s4s4s4s2 0>;
	phy-names = "csis_dphy";

	/* without PAF HW */
	sensor2_ch_mode0: sensor2-ch-mode0 {
		reg = <0x170C4000 0x100>, /* DMA3 VC0 */
			<0x170C4400 0x100>, /* DMA3 Common */
			<0x170C4100 0x100>, /* DMA3 VC1 */
			<0x170C4400 0x100>, /* DMA3 Common */
			<0x170C4200 0x100>, /* DMA3 VC2 */
			<0x170C4400 0x100>, /* DMA3 Common */
			<0x170C4300 0x100>, /* DMA3 VC3 */
			<0x170C4400 0x100>; /* DMA3 Common */
		mux_reg = <0x17020420 0x4>; /* DMA3 input mux */
	};

	/* with PAF HW */
	sensor2_ch_mode1: sensor2-ch-mode1 {
		reg = <0x170C4000 0x100>, /* DMA3 VC0 */
			<0x170C4400 0x100>, /* DMA3 Common */
			<0x170C4100 0x100>, /* DMA3 VC1 */
			<0x170C4400 0x100>, /* DMA3 Common */
			<0x170C4200 0x100>, /* DMA3 VC2 */
			<0x170C4400 0x100>, /* DMA3 Common */
			<0x170C4300 0x100>, /* DMA3 VC3 */
			<0x170C4400 0x100>; /* DMA3 Common */
		mux_reg = <0x17020420 0x4>; /* DMA3 input mux */
	};
};

/* Reseved: FRONT SUB */
&is_sensor3 {
	#address-cells = <1>;
	#size-cells = <1>;
	scenario = <SENSOR_SCENARIO_NORMAL>;    /* Normal, Vision, OIS etc */
	id = <5>;
	csi_ch = <1>;
	dma_ch = <1 1 1 1>;
	vc_ch = <0 1 2 3>;
	flite_ch = <FLITE_ID_NOTHING>;
	is_bns = <0>;
	status = "okay";
};

/* ULTRA WIDE CAMERA */
&is_sensor4 {
	#address-cells = <1>;
	#size-cells = <1>;
	scenario = <SENSOR_SCENARIO_NORMAL>;    /* Normal, Vision, OIS etc */
	id = <4>;
	csi_ch = <4>;
	dma_ch = <0 0 0 0>;
	vc_ch = <0 1 2 3>;
	flite_ch = <FLITE_ID_NOTHING>;
	is_bns = <0>;
	status = "okay";
	use_cphy = <1>;

	reg = <0x0 0x17070000 0x1000>, /* MIPI-CSI4 */
			<0x0 0x170D0000 0x10000>; /* PHY: M0S4S4S4S4S4S2 */
	reg-names = "csi", "phy";

	phys = <&mipi_phy_csis4_m0s4s4s4s4s4s2 0>;
	phy-names = "csis_dphy";

	interrupts = <0 INTREQ__CSIS4 IRQ_TYPE_LEVEL_HIGH>, /* MIPI-CSI4 */
			<0 INTREQ__CSIS_DMA0 IRQ_TYPE_LEVEL_HIGH>,
			<0 INTREQ__CSIS_DMA0 IRQ_TYPE_LEVEL_HIGH>,
			<0 INTREQ__CSIS_DMA0 IRQ_TYPE_LEVEL_HIGH>,
			<0 INTREQ__CSIS_DMA0 IRQ_TYPE_LEVEL_HIGH>;
	interrupt-names = "csi",
			"mode0_VC0", "mode0_VC1","mode0_VC2","mode0_VC3";

	/* without PAF HW */
	sensor4_ch_mode0: sensor4-ch-mode0 {
		reg = <0x170C1000 0x100>, /* DMA0 VC0 */
			<0x170C1400 0x100>, /* DMA0 Common */
			<0x170C1100 0x100>, /* DMA0 VC1 */
			<0x170C1400 0x100>, /* DMA0 Common */
			<0x170C1200 0x100>, /* DMA0 VC2 */
			<0x170C1400 0x100>, /* DMA0 Common */
			<0x170C1300 0x100>, /* DMA0 VC3 */
			<0x170C1400 0x100>; /* DMA0 Common */
		mux_reg = <0x17020414 0x4>; /* DMA0 input mux */
	};
};

/* REAR TOF */
&is_sensor5 {
	#address-cells = <1>;
	#size-cells = <1>;

	reg = <0x0 0x17080000 0x1000>, /* MIPI-CSI5 */
	<0x0 0x170D0000 0x10000>; /* PHY: M0S4S4S4S4S4S2 */

	phys = <&mipi_phy_csis5_m0s4s4s4s4s4s2 0>;
	scenario = <SENSOR_SCENARIO_VISION>;    /* Normal, Vision, OIS etc */
	id =  <3>;

	csi_ch = <5>;
	dma_ch = <1 1 1 1>;
	vc_ch = <0 1 2 3>;
	flite_ch = <FLITE_ID_NOTHING>;
	is_bns = <0>;
	status = "okay";

	interrupts = <0 INTREQ__CSIS5 IRQ_TYPE_LEVEL_HIGH>, /* MIPI-CSI5 */
			<0 INTREQ__CSIS_DMA1 IRQ_TYPE_LEVEL_HIGH>,
			<0 INTREQ__CSIS_DMA1 IRQ_TYPE_LEVEL_HIGH>,
			<0 INTREQ__CSIS_DMA1 IRQ_TYPE_LEVEL_HIGH>,
			<0 INTREQ__CSIS_DMA1 IRQ_TYPE_LEVEL_HIGH>;

	/* without PAF HW */
	sensor5_ch_mode0: sensor5-ch-mode0 {
		reg = <0x170C2000 0x100>, /* DMA1 VC0 */
			<0x170C2400 0x100>, /* DMA1 Common */
			<0x170C2100 0x100>, /* DMA1 VC1 */
			<0x170C2400 0x100>, /* DMA1 Common */
			<0x170C2200 0x100>, /* DMA1 VC2 */
			<0x170C2400 0x100>, /* DMA1 Common */
			<0x170C2300 0x100>, /* DMA1 VC3 */
			<0x170C2400 0x100>; /* DMA1 Common */
		mux_reg = <0x17020418 0x4>; /* DMA1 input mux */
	};
};

&exynos_is {
	secure_mem_info = <0x96000000 0x3200000>;
	non_secure_mem_info = <0x0 0x0>;
	vender {
		rear_sensor_id = <52>;	/* 2LD */
		front_sensor_id = <38>; /* 3J1 */
		rear2_sensor_id = <54>;	/* GW2 */
		rear3_sensor_id = <53>; /* 2LA */
		rear_tof_sensor_id = <122>; /* IMX518 */
		use_module_check;
		use_ois;
		check_sensor_vendor;
		ois_sensor_index = <0>;
		aperture_sensor_index = <0>;
		mcu_sensor_index = <0>;

		max_supported_camera = <9>;
		supported_cameraId = <0 2 3 20 21 23 50 52 80>;
		ois_gyro_list = <0x00 0x00 0x01 0x01 0x01>;
		/*
		* Wide(0)
		* Front(1) - not available for factory
		* U Wide(2)
		* Front 80(3) - available for factory
		* Rear ToF(4) - not available for factory
		* Front Secure(5) - not available for factory
		* Dual Zoom(20)
		* Dual Portrait Tele(21) - Main Tele/Sub Wide
		* Dual Portrait Wide(23) - Main Wide/Sub U Wide
		* Tele 2x2(50)
		* Tele 17.9(52)
		* REAR ToF(80)
		*/

		/* sysfs camera id */
		max_camera_num = <9>;
		camera_info0 {			// 0 : sysfs rear
			internal_id = <0>;	// 0 : wide
			isp = <0>;			/* 0 : INT , 1 : EXT , 2 : SOC */
			cal_memory = <2>;	/* 0 : N , 1 : FROM , 2 : EEPROM , 3 : OTP  */
			read_version = <0>;	/* 0 : SYSFS , 1 : CAMON */
			core_voltage = <0>;	/* 0 : N , 1 : Y  */
			upgrade = <0>;		/* 0 : N , 1 : SYSFS , 2 : CAMON */
			fw_write = <0>;		/* 0 : N,  1 : OS, 2 : SD, 3 : ALL */
			fw_dump = <0>;		/* 0 : N , 1 : Y  */
			companion = <0>;	/* 0 : N , 1 : Y  */
			ois = <1>;			/* 0 : N , 1 : Y  */
			valid = <1>;		/* 0 : INVALID , 1 : VALID   */
		};
		camera_info1 {			// 1 : sysfs front
			internal_id = <1>;	// 1 : front master
			isp = <0>;			/* 0 : INT , 1 : EXT , 2 : SOC */
			cal_memory = <2>;	/* 0 : N , 1 : FROM , 2 : EEPROM , 3 : OTP  */
			read_version = <0>;	/* 0 : SYSFS , 1 : CAMON */
			core_voltage = <0>;	/* 0 : N , 1 : Y  */
			upgrade = <0>;		/* 0 : N , 1 : SYSFS , 2 : CAMON */
			fw_write = <0>;		/* 0 : N,  1 : OS, 2 : SD, 3 : ALL */
			fw_dump = <0>;		/* 0 : N , 1 : Y  */
			companion = <0>;	/* 0 : N , 1 : Y  */
			ois = <0>;			/* 0 : N , 1 : Y  */
			valid = <1>;		/* 0 : INVALID , 1 : VALID   */
		};
		camera_info2 {			// 2 : sysfs rear2
			internal_id = <4>;	// 4 : ultra wide
			isp = <0>;			/* 0 : INT , 1 : EXT , 2 : SOC */
			cal_memory = <2>;	/* 0 : N , 1 : FROM , 2 : EEPROM , 3 : OTP  */
			read_version = <0>;	/* 0 : SYSFS , 1 : CAMON */
			core_voltage = <0>;	/* 0 : N , 1 : Y  */
			upgrade = <0>;		/* 0 : N , 1 : SYSFS , 2 : CAMON */
			fw_write = <0>;		/* 0 : N,  1 : OS, 2 : SD, 3 : ALL */
			fw_dump = <0>;		/* 0 : N , 1 : Y  */
			companion = <0>;	/* 0 : N , 1 : Y  */
			ois = <0>;			/* 0 : N , 1 : Y  */
			valid = <1>;		/* 0 : INVALID , 1 : VALID   */
		};
		camera_info3 {			// 3 : sysfs front2
			internal_id = <3>;	// 3 : front sub
			isp = <0>;			/* 0 : INT , 1 : EXT , 2 : SOC */
			cal_memory = <2>;	/* 0 : N , 1 : FROM , 2 : EEPROM , 3 : OTP  */
			read_version = <0>;	/* 0 : SYSFS , 1 : CAMON */
			core_voltage = <0>;	/* 0 : N , 1 : Y  */
			upgrade = <0>;		/* 0 : N , 1 : SYSFS , 2 : CAMON */
			fw_write = <0>;		/* 0 : N,  1 : OS, 2 : SD, 3 : ALL */
			fw_dump = <0>;		/* 0 : N , 1 : Y  */
			companion = <0>;	/* 0 : N , 1 : Y  */
			ois = <0>;			/* 0 : N , 1 : Y  */
			valid = <1>;		/* 0 : INVALID , 1 : VALID   */
		};
		camera_info4 {			// 4 : sysfs rear3
			internal_id = <2>;	// 4 : tele
			isp = <0>;			/* 0 : INT , 1 : EXT , 2 : SOC */
			cal_memory = <2>;	/* 0 : N , 1 : FROM , 2 : EEPROM , 3 : OTP  */
			read_version = <0>;	/* 0 : SYSFS , 1 : CAMON */
			core_voltage = <0>;	/* 0 : N , 1 : Y  */
			upgrade = <0>;		/* 0 : N , 1 : SYSFS , 2 : CAMON */
			fw_write = <0>;		/* 0 : N,  1 : OS, 2 : SD, 3 : ALL */
			fw_dump = <0>;		/* 0 : N , 1 : Y  */
			companion = <0>;	/* 0 : N , 1 : Y  */
			ois = <1>;			/* 0 : N , 1 : Y  */
			valid = <1>;		/* 0 : INVALID , 1 : VALID   */
		};
		camera_info5 {			// 5 : sysfs front3
			valid = <0>;		/* 0 : INVALID , 1 : VALID   */
		};
		camera_info6 {			// 6 : sysfs rear4
			valid = <0>;		/* 0 : INVALID , 1 : VALID   */
		};
		camera_info7 {			// 7 : sysfs front4
			valid = <0>;		/* 0 : INVALID , 1 : VALID   */
		};
		camera_info8 {			// 8 : sysfs rear tof
			internal_id = <8>;	// 3 : rear tof
			isp = <0>;			/* 0 : INT , 1 : EXT , 2 : SOC */
			cal_memory = <2>;	/* 0 : N , 1 : FROM , 2 : EEPROM , 3 : OTP  */
			read_version = <0>;	/* 0 : SYSFS , 1 : CAMON */
			core_voltage = <0>;	/* 0 : N , 1 : Y  */
			upgrade = <0>;		/* 0 : N , 1 : SYSFS , 2 : CAMON */
			fw_write = <0>;		/* 0 : N,  1 : OS, 2 : SD, 3 : ALL */
			fw_dump = <0>;		/* 0 : N , 1 : Y  */
			companion = <0>;	/* 0 : N , 1 : Y  */
			ois = <0>;			/* 0 : N , 1 : Y  */
			valid = <1>;		/* 0 : INVALID , 1 : VALID   */
		};
	};

	lic_offsets {
		/* 3AA = <setA lic offset0, setA lic offset1, set A trigger context */
		/*		setB lic offset0, setB lic offset1, set B trigger context> */
		/* 4672: 4640x4352 */
		/* 5824: 5804x4352 */
		3AA = <6848 13696 1 6848 13696 2>;
	};

	is_dvfs {
		#define DVFS_INT_CAM_L0 690000
		#define DVFS_INT_CAM_L1 680000
		#define DVFS_INT_CAM_L2 670000
		#define DVFS_INT_CAM_L3 660000
		#define DVFS_INT_CAM_L4 650000
		#define DVFS_INT_CAM_L5 640000
		#define DVFS_INT_CAM_L6 630000
		#define DVFS_INT_CAM_L7 620000

		#define DVFS_TNR_L0 690000
		#define DVFS_TNR_L1 680000
		#define DVFS_TNR_L2 670000
		#define DVFS_TNR_L3 660000
		#define DVFS_TNR_L4 650000
		#define DVFS_TNR_L5 640000
		#define DVFS_TNR_L6 630000
		#define DVFS_TNR_L7 620000

		#define DVFS_INT_L0 533000
		#define DVFS_INT_L1 400000
		#define DVFS_INT_L2 333000
		#define DVFS_INT_L3 266000
		#define DVFS_INT_L4 200000
		#define DVFS_INT_L5 133000

		#define DVFS_CAM_L0 690000
		#define DVFS_CAM_L1 680000
		#define DVFS_CAM_L2 670000
		#define DVFS_CAM_L3 660000
		#define DVFS_CAM_L4 650000
		#define DVFS_CAM_L5 640000

		#define DVFS_MIF_L0 2730000
		#define DVFS_MIF_L1 2535000
		#define DVFS_MIF_L2 2288000
		#define DVFS_MIF_L3 2028000
		#define DVFS_MIF_L4 1716000
		#define DVFS_MIF_L5 1539000
		#define DVFS_MIF_L6 1352000
		#define DVFS_MIF_L7 1014000
		#define DVFS_MIF_L8 845000
		#define DVFS_MIF_L9 676000
		#define DVFS_MIF_L10 546000
		#define DVFS_MIF_L11 421000

		table0 {
			desc = "dvfs table v0.3.0 v1.0 for 12M/16M";

			default_int_cam = <DVFS_INT_CAM_L3>;
			default_tnr = <DVFS_TNR_L3>;
			default_cam = <DVFS_CAM_L0>;
			default_mif = <DVFS_MIF_L0>;
			default_int = <DVFS_INT_L0>;
			default_hpg = <1>;

			front2_preview_int_cam = <DVFS_INT_CAM_L5>;
			front2_preview_tnr = <DVFS_TNR_L5>;
			front2_preview_cam = <DVFS_CAM_L4>;
			front2_preview_mif = <DVFS_MIF_L3>;
			front2_preview_int = <DVFS_INT_L4>;
			front2_preview_hpg = <1>;

			front2_capture_int_cam = <DVFS_INT_CAM_L3>;
			front2_capture_tnr = <DVFS_TNR_L3>;
			front2_capture_cam = <DVFS_CAM_L4>;
			front2_capture_mif = <DVFS_MIF_L0>;
			front2_capture_int = <DVFS_INT_L4>;
			front2_capture_hpg = <1>;

			front2_video_int_cam = <DVFS_INT_CAM_L5>;
			front2_video_tnr = <DVFS_TNR_L5>;
			front2_video_cam = <DVFS_CAM_L4>;
			front2_video_mif = <DVFS_MIF_L5>;
			front2_video_int = <DVFS_INT_L4>;
			front2_video_hpg = <1>;

			front2_video_capture_int_cam = <DVFS_INT_CAM_L3>;
			front2_video_capture_tnr = <DVFS_TNR_L3>;
			front2_video_capture_cam = <DVFS_CAM_L4>;
			front2_video_capture_mif = <DVFS_MIF_L0>;
			front2_video_capture_int = <DVFS_INT_L4>;
			front2_video_capture_hpg = <1>;

			front_preview_int_cam = <DVFS_INT_CAM_L5>;
			front_preview_tnr = <DVFS_TNR_L5>;
			front_preview_cam = <DVFS_CAM_L4>;
			front_preview_mif = <DVFS_MIF_L6>;
			front_preview_int = <DVFS_INT_L4>;
			front_preview_hpg = <1>;

			front_preview_full_int_cam = <DVFS_INT_CAM_L5>;
			front_preview_full_tnr = <DVFS_TNR_L5>;
			front_preview_full_cam = <DVFS_CAM_L4>;
			front_preview_full_mif = <DVFS_MIF_L5>;
			front_preview_full_int = <DVFS_INT_L4>;
			front_preview_full_hpg = <1>;

			front_capture_int_cam = <DVFS_INT_CAM_L3>;
			front_capture_tnr = <DVFS_TNR_L3>;
			front_capture_cam = <DVFS_CAM_L4>;
			front_capture_mif = <DVFS_MIF_L0>;
			front_capture_int = <DVFS_INT_L4>;
			front_capture_hpg = <1>;

			front_video_int_cam = <DVFS_INT_CAM_L5>;
			front_video_tnr = <DVFS_TNR_L5>;
			front_video_cam = <DVFS_CAM_L4>;
			front_video_mif = <DVFS_MIF_L5>;
			front_video_int = <DVFS_INT_L4>;
			front_video_hpg = <1>;

			front_video_whd_int_cam = <DVFS_INT_CAM_L5>;
			front_video_whd_tnr = <DVFS_TNR_L5>;
			front_video_whd_cam = <DVFS_CAM_L4>;
			front_video_whd_mif = <DVFS_MIF_L5>;
			front_video_whd_int = <DVFS_INT_L4>;
			front_video_whd_hpg = <1>;

			front_video_uhd_int_cam = <DVFS_INT_CAM_L5>;
			front_video_uhd_tnr = <DVFS_TNR_L5>;
			front_video_uhd_cam = <DVFS_CAM_L4>;
			front_video_uhd_mif = <DVFS_MIF_L5>;
			front_video_uhd_int = <DVFS_INT_L4>;
			front_video_uhd_hpg = <1>;

			front_video_fhd_60fps_int_cam = <DVFS_INT_CAM_L5>;
			front_video_fhd_60fps_tnr = <DVFS_TNR_L5>;
			front_video_fhd_60fps_cam = <DVFS_CAM_L4>;
			front_video_fhd_60fps_mif = <DVFS_MIF_L5>;
			front_video_fhd_60fps_int = <DVFS_INT_L4>;
			front_video_fhd_60fps_hpg = <1>;

			front_video_uhd_60fps_int_cam = <DVFS_INT_CAM_L4>;
			front_video_uhd_60fps_tnr = <DVFS_TNR_L4>;
			front_video_uhd_60fps_cam = <DVFS_CAM_L4>;
			front_video_uhd_60fps_mif = <DVFS_MIF_L4>;
			front_video_uhd_60fps_int = <DVFS_INT_L4>;
			front_video_uhd_60fps_hpg = <1>;

			front_video_capture_int_cam = <DVFS_INT_CAM_L3>;
			front_video_capture_tnr = <DVFS_TNR_L3>;
			front_video_capture_cam = <DVFS_CAM_L4>;
			front_video_capture_mif = <DVFS_MIF_L0>;
			front_video_capture_int = <DVFS_INT_L4>;
			front_video_capture_hpg = <1>;

			front_video_whd_capture_int_cam = <DVFS_INT_CAM_L3>;
			front_video_whd_capture_tnr = <DVFS_TNR_L3>;
			front_video_whd_capture_cam = <DVFS_CAM_L4>;
			front_video_whd_capture_mif = <DVFS_MIF_L0>;
			front_video_whd_capture_int = <DVFS_INT_L4>;
			front_video_whd_capture_hpg = <1>;

			front_video_uhd_capture_int_cam = <DVFS_INT_CAM_L3>;
			front_video_uhd_capture_tnr = <DVFS_TNR_L3>;
			front_video_uhd_capture_cam = <DVFS_CAM_L4>;
			front_video_uhd_capture_mif = <DVFS_MIF_L0>;
			front_video_uhd_capture_int = <DVFS_INT_L4>;
			front_video_uhd_capture_hpg = <1>;

			front_video_uhd_60fps_capture_int_cam = <DVFS_INT_CAM_L3>;
			front_video_uhd_60fps_capture_tnr = <DVFS_TNR_L3>;
			front_video_uhd_60fps_capture_cam = <DVFS_CAM_L4>;
			front_video_uhd_60fps_capture_mif = <DVFS_MIF_L3>;
			front_video_uhd_60fps_capture_int = <DVFS_INT_L4>;
			front_video_uhd_60fps_capture_hpg = <1>;

			front_video_fhd_60fps_capture_int_cam = <DVFS_INT_CAM_L3>;
			front_video_fhd_60fps_capture_tnr = <DVFS_TNR_L3>;
			front_video_fhd_60fps_capture_cam = <DVFS_CAM_L4>;
			front_video_fhd_60fps_capture_mif = <DVFS_MIF_L3>;
			front_video_fhd_60fps_capture_int = <DVFS_INT_L4>;
			front_video_fhd_60fps_capture_hpg = <1>;

			front_dual_sync_preview_int_cam = <DVFS_INT_CAM_L5>;
			front_dual_sync_preview_tnr = <DVFS_TNR_L5>;
			front_dual_sync_preview_cam = <DVFS_CAM_L4>;
			front_dual_sync_preview_mif = <DVFS_MIF_L3>;
			front_dual_sync_preview_int = <DVFS_INT_L4>;
			front_dual_sync_preview_hpg = <1>;

			front_dual_sync_capture_int_cam = <DVFS_INT_CAM_L3>;
			front_dual_sync_capture_tnr = <DVFS_TNR_L3>;
			front_dual_sync_capture_cam = <DVFS_CAM_L4>;
			front_dual_sync_capture_mif = <DVFS_MIF_L3>;
			front_dual_sync_capture_int = <DVFS_INT_L4>;
			front_dual_sync_capture_hpg = <1>;

			front_dual_sync_video_fhd_int_cam = <DVFS_INT_CAM_L5>;
			front_dual_sync_video_fhd_tnr = <DVFS_TNR_L5>;
			front_dual_sync_video_fhd_cam = <DVFS_CAM_L4>;
			front_dual_sync_video_fhd_mif = <DVFS_MIF_L3>;
			front_dual_sync_video_fhd_int = <DVFS_INT_L4>;
			front_dual_sync_video_fhd_hpg = <1>;

			front_dual_sync_video_fhd_capture_int_cam = <DVFS_INT_CAM_L3>;
			front_dual_sync_video_fhd_capture_tnr = <DVFS_TNR_L3>;
			front_dual_sync_video_fhd_capture_cam = <DVFS_CAM_L4>;
			front_dual_sync_video_fhd_capture_mif = <DVFS_MIF_L3>;
			front_dual_sync_video_fhd_capture_int = <DVFS_INT_L4>;
			front_dual_sync_video_fhd_capture_hpg = <1>;

			front_vt1_int_cam = <DVFS_INT_CAM_L5>;
			front_vt1_tnr = <DVFS_TNR_L5>;
			front_vt1_cam = <DVFS_CAM_L4>;
			front_vt1_mif = <DVFS_MIF_L7>;
			front_vt1_int = <DVFS_INT_L4>;
			front_vt1_hpg = <1>;

			front_vt2_int_cam = <DVFS_INT_CAM_L5>;
			front_vt2_tnr = <DVFS_TNR_L5>;
			front_vt2_cam = <DVFS_CAM_L4>;
			front_vt2_mif = <DVFS_MIF_L7>;
			front_vt2_int = <DVFS_INT_L4>;
			front_vt2_hpg = <1>;

			front_vt4_int_cam = <DVFS_INT_CAM_L5>;
			front_vt4_tnr = <DVFS_TNR_L5>;
			front_vt4_cam = <DVFS_CAM_L4>;
			front_vt4_mif = <DVFS_MIF_L7>;
			front_vt4_int = <DVFS_INT_L4>;
			front_vt4_hpg = <1>;

			front_preview_high_speed_fps_int_cam = <DVFS_INT_CAM_L1>;
			front_preview_high_speed_fps_tnr = <DVFS_TNR_L1>;
			front_preview_high_speed_fps_cam = <DVFS_CAM_L1>;
			front_preview_high_speed_fps_mif = <DVFS_MIF_L1>;
			front_preview_high_speed_fps_int = <DVFS_INT_L1>;
			front_preview_high_speed_fps_hpg = <1>;

			front_video_high_speed_120fps_int_cam = <DVFS_INT_CAM_L3>;
			front_video_high_speed_120fps_tnr = <DVFS_TNR_L3>;
			front_video_high_speed_120fps_cam = <DVFS_CAM_L4>;	/* X1/Y2/C1/C2 CAM(L4), Z3 CAM(L3) */
			front_video_high_speed_120fps_mif = <DVFS_MIF_L3>;
			front_video_high_speed_120fps_int = <DVFS_INT_L4>;
			front_video_high_speed_120fps_hpg = <1>;

			rear3_preview_fhd_int_cam = <DVFS_INT_CAM_L3>;
			rear3_preview_fhd_tnr = <DVFS_TNR_L3>;
			rear3_preview_fhd_cam = <DVFS_CAM_L1>;	/* OTF */
			rear3_preview_fhd_mif = <DVFS_MIF_L3>;
			rear3_preview_fhd_int = <DVFS_INT_L2>;
			rear3_preview_fhd_hpg = <1>;

			rear3_capture_int_cam = <DVFS_INT_CAM_L3>;
			rear3_capture_tnr = <DVFS_TNR_L3>;
			rear3_capture_cam = <DVFS_CAM_L1>;		/* OTF */
			rear3_capture_mif = <DVFS_MIF_L0>;
			rear3_capture_int = <DVFS_INT_L2>;
			rear3_capture_hpg = <1>;

			rear3_video_fhd_int_cam = <DVFS_INT_CAM_L5>;
			rear3_video_fhd_tnr = <DVFS_TNR_L5>;
			rear3_video_fhd_cam = <DVFS_CAM_L1>;	/* OTF */
			rear3_video_fhd_mif = <DVFS_MIF_L5>;
			rear3_video_fhd_int = <DVFS_INT_L2>;
			rear3_video_fhd_hpg = <1>;

			rear3_video_fhd_capture_int_cam = <DVFS_INT_CAM_L3>;
			rear3_video_fhd_capture_tnr = <DVFS_TNR_L3>;
			rear3_video_fhd_capture_cam = <DVFS_CAM_L1>;	/* OTF */
			rear3_video_fhd_capture_mif = <DVFS_MIF_L0>;
			rear3_video_fhd_capture_int = <DVFS_INT_L2>;
			rear3_video_fhd_capture_hpg = <1>;

			rear2_preview_fhd_int_cam = <DVFS_INT_CAM_L3>;
			rear2_preview_fhd_tnr = <DVFS_TNR_L3>;
			rear2_preview_fhd_cam = <DVFS_CAM_L1>;	/* OTF */
			rear2_preview_fhd_mif = <DVFS_MIF_L5>;
			rear2_preview_fhd_int = <DVFS_INT_L2>;
			rear2_preview_fhd_hpg = <1>;

			rear2_capture_int_cam = <DVFS_INT_CAM_L3>;
			rear2_capture_tnr = <DVFS_TNR_L3>;
			rear2_capture_cam = <DVFS_CAM_L1>;	/* OTF */
			rear2_capture_mif = <DVFS_MIF_L0>;
			rear2_capture_int = <DVFS_INT_L2>;
			rear2_capture_hpg = <1>;

			rear2_video_fhd_int_cam = <DVFS_INT_CAM_L5>;
			rear2_video_fhd_tnr = <DVFS_TNR_L5>;
			rear2_video_fhd_cam = <DVFS_CAM_L1>;	/* OTF */
			rear2_video_fhd_mif = <DVFS_MIF_L5>;
			rear2_video_fhd_int = <DVFS_INT_L2>;
			rear2_video_fhd_hpg = <1>;

			rear2_video_uhd_8k_int_cam = <DVFS_INT_CAM_L3>;
			rear2_video_uhd_8k_tnr = <DVFS_TNR_L3>;
			rear2_video_uhd_8k_cam = <DVFS_CAM_L1>;	/* OTF */
			rear2_video_uhd_8k_mif = <DVFS_MIF_L0>;
			rear2_video_uhd_8k_int = <DVFS_INT_L2>;
			rear2_video_uhd_8k_hpg = <1>;

			rear2_video_fhd_capture_int_cam = <DVFS_INT_CAM_L3>;
			rear2_video_fhd_capture_tnr = <DVFS_TNR_L3>;
			rear2_video_fhd_capture_cam = <DVFS_CAM_L1>;	/* OTF */
			rear2_video_fhd_capture_mif = <DVFS_MIF_L0>;
			rear2_video_fhd_capture_int = <DVFS_INT_L2>;
			rear2_video_fhd_capture_hpg = <1>;

			rear2_video_uhd_8k_capture_int_cam = <DVFS_INT_CAM_L2>;
			rear2_video_uhd_8k_capture_tnr = <DVFS_TNR_L2>;
			rear2_video_uhd_8k_capture_cam = <DVFS_CAM_L1>;	/* OTF */
			rear2_video_uhd_8k_capture_mif = <DVFS_MIF_L0>;
			rear2_video_uhd_8k_capture_int = <DVFS_INT_L0>;
			rear2_video_uhd_8k_capture_hpg = <1>;

			rear_preview_fhd_int_cam = <DVFS_INT_CAM_L5>;
			rear_preview_fhd_tnr = <DVFS_TNR_L5>;
			rear_preview_fhd_cam = <DVFS_CAM_L1>;	/* VOTF */
			rear_preview_fhd_mif = <DVFS_MIF_L5>;
			rear_preview_fhd_int = <DVFS_INT_L2>;
			rear_preview_fhd_hpg = <1>;

			rear_preview_whd_int_cam = <DVFS_INT_CAM_L3>;
			rear_preview_whd_tnr = <DVFS_TNR_L3>;
			rear_preview_whd_cam = <DVFS_CAM_L1>;	/* VOTF */
			rear_preview_whd_mif = <DVFS_MIF_L3>;
			rear_preview_whd_int = <DVFS_INT_L2>;
			rear_preview_whd_hpg = <1>;

			rear_preview_uhd_int_cam = <DVFS_INT_CAM_L3>;
			rear_preview_uhd_tnr = <DVFS_TNR_L3>;
			rear_preview_uhd_cam = <DVFS_CAM_L1>;	/* VOTF */
			rear_preview_uhd_mif = <DVFS_MIF_L3>;
			rear_preview_uhd_int = <DVFS_INT_L2>;
			rear_preview_uhd_hpg = <1>;

			rear_preview_uhd_60fps_int_cam = <DVFS_INT_CAM_L3>;
			rear_preview_uhd_60fps_tnr = <DVFS_TNR_L2>;
			rear_preview_uhd_60fps_cam = <DVFS_CAM_L1>;	/* VOTF */
			rear_preview_uhd_60fps_mif = <DVFS_MIF_L3>;
			rear_preview_uhd_60fps_int = <DVFS_INT_L2>;
			rear_preview_uhd_60fps_hpg = <1>;

			rear_preview_full_int_cam = <DVFS_INT_CAM_L3>;
			rear_preview_full_tnr = <DVFS_TNR_L3>;
			rear_preview_full_cam = <DVFS_CAM_L1>;	/* VOTF */
			rear_preview_full_mif = <DVFS_MIF_L3>;
			rear_preview_full_int = <DVFS_INT_L2>;
			rear_preview_full_hpg = <1>;

			rear_capture_int_cam = <DVFS_INT_CAM_L3>;
			rear_capture_tnr = <DVFS_TNR_L3>;
			rear_capture_cam = <DVFS_CAM_L1>;	/* VOTF */
			rear_capture_mif = <DVFS_MIF_L0>;
			rear_capture_int = <DVFS_INT_L2>;
			rear_capture_hpg = <1>;

			rear_video_fhd_int_cam = <DVFS_INT_CAM_L5>;
			rear_video_fhd_tnr = <DVFS_TNR_L5>;
			rear_video_fhd_cam = <DVFS_CAM_L2>;	/* VOTF */
			rear_video_fhd_mif = <DVFS_MIF_L6>;
			rear_video_fhd_int = <DVFS_INT_L3>;
			rear_video_fhd_hpg = <1>;

			rear_video_hdr_int_cam = <DVFS_INT_CAM_L5>;
			rear_video_hdr_tnr = <DVFS_TNR_L5>;
			rear_video_hdr_cam = <DVFS_CAM_L1>;	/* VOTF */
			rear_video_hdr_mif = <DVFS_MIF_L5>;
			rear_video_hdr_int = <DVFS_INT_L2>;
			rear_video_hdr_hpg = <1>;

			rear_video_whd_int_cam = <DVFS_INT_CAM_L3>;
			rear_video_whd_tnr = <DVFS_TNR_L3>;
			rear_video_whd_cam = <DVFS_CAM_L1>;	/* VOTF */
			rear_video_whd_mif = <DVFS_MIF_L5>;
			rear_video_whd_int = <DVFS_INT_L2>;
			rear_video_whd_hpg = <1>;

			rear_video_uhd_int_cam = <DVFS_INT_CAM_L5>;
			rear_video_uhd_tnr = <DVFS_TNR_L5>;
			rear_video_uhd_cam = <DVFS_CAM_L2>;	/* VOTF */
			rear_video_uhd_mif = <DVFS_MIF_L5>;
			rear_video_uhd_int = <DVFS_INT_L3>;
			rear_video_uhd_hpg = <1>;

			rear_video_uhd_60fps_int_cam = <DVFS_INT_CAM_L3>;
			rear_video_uhd_60fps_tnr = <DVFS_TNR_L3>;
			rear_video_uhd_60fps_cam = <DVFS_CAM_L1>;	/* OTF */
			rear_video_uhd_60fps_mif = <DVFS_MIF_L3>;	/* video snapshot */
			rear_video_uhd_60fps_int = <DVFS_INT_L2>;	/* video snapshot */
			rear_video_uhd_60fps_hpg = <1>;

			rear_video_uhd_8k_int_cam = <DVFS_INT_CAM_L3>;
			rear_video_uhd_8k_tnr = <DVFS_TNR_L3>;
			rear_video_uhd_8k_cam = <DVFS_CAM_L1>;	/* VOTF */
			rear_video_uhd_8k_mif = <DVFS_MIF_L0>;
			rear_video_uhd_8k_int = <DVFS_INT_L2>;
			rear_video_uhd_8k_hpg = <1>;

			rear_video_fhd_capture_int_cam = <DVFS_INT_CAM_L3>;
			rear_video_fhd_capture_tnr = <DVFS_TNR_L3>;
			rear_video_fhd_capture_cam = <DVFS_CAM_L1>;	/* VOTF */
			rear_video_fhd_capture_mif = <DVFS_MIF_L0>;
			rear_video_fhd_capture_int = <DVFS_INT_L2>;
			rear_video_fhd_capture_hpg = <1>;

			rear_video_hdr_capture_int_cam = <DVFS_INT_CAM_L3>;
			rear_video_hdr_capture_tnr = <DVFS_TNR_L3>;
			rear_video_hdr_capture_cam = <DVFS_CAM_L1>;	/* VOTF */
			rear_video_hdr_capture_mif = <DVFS_MIF_L0>;
			rear_video_hdr_capture_int = <DVFS_INT_L2>;
			rear_video_hdr_capture_hpg = <1>;

			rear_video_whd_capture_int_cam = <DVFS_INT_CAM_L3>;
			rear_video_whd_capture_tnr = <DVFS_TNR_L3>;
			rear_video_whd_capture_cam = <DVFS_CAM_L1>;	/* VOTF */
			rear_video_whd_capture_mif = <DVFS_MIF_L0>;
			rear_video_whd_capture_int = <DVFS_INT_L2>;
			rear_video_whd_capture_hpg = <1>;

			rear_video_uhd_capture_int_cam = <DVFS_INT_CAM_L3>;
			rear_video_uhd_capture_tnr = <DVFS_TNR_L3>;
			rear_video_uhd_capture_cam = <DVFS_CAM_L1>;	/* VOTF */
			rear_video_uhd_capture_mif = <DVFS_MIF_L0>;
			rear_video_uhd_capture_int = <DVFS_INT_L2>;
			rear_video_uhd_capture_hpg = <1>;

			rear_video_uhd_8k_capture_int_cam = <DVFS_INT_CAM_L2>;
			rear_video_uhd_8k_capture_tnr = <DVFS_TNR_L2>;
			rear_video_uhd_8k_capture_cam = <DVFS_CAM_L1>;	/* VOTF */
			rear_video_uhd_8k_capture_mif = <DVFS_MIF_L0>;
			rear_video_uhd_8k_capture_int = <DVFS_INT_L0>;
			rear_video_uhd_8k_capture_hpg = <1>;

			dual_preview_int_cam = <DVFS_INT_CAM_L3>;
			dual_preview_tnr = <DVFS_TNR_L3>;
			dual_preview_cam = <DVFS_CAM_L1>;	/* OTF */
			dual_preview_mif = <DVFS_MIF_L0>;
			dual_preview_int = <DVFS_INT_L0>;
			dual_preview_hpg = <1>;

			dual_capture_int_cam = <DVFS_INT_CAM_L3>;
			dual_capture_tnr = <DVFS_TNR_L3>;
			dual_capture_cam = <DVFS_CAM_L1>;	/* OTF */
			dual_capture_mif = <DVFS_MIF_L0>;
			dual_capture_int = <DVFS_INT_L0>;
			dual_capture_hpg = <1>;

			dual_video_fhd_int_cam = <DVFS_INT_CAM_L3>;
			dual_video_fhd_tnr = <DVFS_TNR_L3>;
			dual_video_fhd_cam = <DVFS_CAM_L1>;	/* OTF */
			dual_video_fhd_mif = <DVFS_MIF_L3>;
			dual_video_fhd_int = <DVFS_INT_L0>;
			dual_video_fhd_hpg = <1>;

			dual_video_fhd_capture_int_cam = <DVFS_INT_CAM_L3>;
			dual_video_fhd_capture_tnr = <DVFS_TNR_L3>;
			dual_video_fhd_capture_cam = <DVFS_CAM_L1>;	/* OTF */
			dual_video_fhd_capture_mif = <DVFS_MIF_L0>;
			dual_video_fhd_capture_int = <DVFS_INT_L0>;
			dual_video_fhd_capture_hpg = <1>;

			dual_video_uhd_int_cam = <DVFS_INT_CAM_L3>;
			dual_video_uhd_tnr = <DVFS_TNR_L3>;
			dual_video_uhd_cam = <DVFS_CAM_L1>;	/* OTF */
			dual_video_uhd_mif = <DVFS_MIF_L3>;
			dual_video_uhd_int = <DVFS_INT_L0>;
			dual_video_uhd_hpg = <1>;

			dual_video_uhd_capture_int_cam = <DVFS_INT_CAM_L3>;
			dual_video_uhd_capture_tnr = <DVFS_TNR_L3>;
			dual_video_uhd_capture_cam = <DVFS_CAM_L1>;	/* OTF */
			dual_video_uhd_capture_mif = <DVFS_MIF_L0>;
			dual_video_uhd_capture_int = <DVFS_INT_L0>;
			dual_video_uhd_capture_hpg = <1>;

			dual_sync_preview_int_cam = <DVFS_INT_CAM_L3>;
			dual_sync_preview_tnr = <DVFS_TNR_L3>;
			dual_sync_preview_cam = <DVFS_CAM_L1>;	/* OTF */
			dual_sync_preview_mif = <DVFS_MIF_L0>;
			dual_sync_preview_int = <DVFS_INT_L0>;
			dual_sync_preview_hpg = <1>;

			dual_sync_capture_int_cam = <DVFS_INT_CAM_L3>;
			dual_sync_capture_tnr = <DVFS_TNR_L3>;
			dual_sync_capture_cam = <DVFS_CAM_L1>;	/* OTF */
			dual_sync_capture_mif = <DVFS_MIF_L0>;
			dual_sync_capture_int = <DVFS_INT_L0>;
			dual_sync_capture_hpg = <1>;

			dual_sync_preview_whd_int_cam = <DVFS_INT_CAM_L3>;
			dual_sync_preview_whd_tnr = <DVFS_TNR_L3>;
			dual_sync_preview_whd_cam = <DVFS_CAM_L1>;	/* OTF */
			dual_sync_preview_whd_mif = <DVFS_MIF_L0>;
			dual_sync_preview_whd_int = <DVFS_INT_L0>;
			dual_sync_preview_whd_hpg = <1>;

			dual_sync_whd_capture_int_cam = <DVFS_INT_CAM_L3>;
			dual_sync_whd_capture_tnr = <DVFS_TNR_L3>;
			dual_sync_whd_capture_cam = <DVFS_CAM_L1>;	/* OTF */
			dual_sync_whd_capture_mif = <DVFS_MIF_L0>;
			dual_sync_whd_capture_int = <DVFS_INT_L0>;
			dual_sync_whd_capture_hpg = <1>;

			dual_sync_video_fhd_int_cam = <DVFS_INT_CAM_L3>;
			dual_sync_video_fhd_tnr = <DVFS_TNR_L3>;
			dual_sync_video_fhd_cam = <DVFS_CAM_L1>;	/* OTF */
			dual_sync_video_fhd_mif = <DVFS_MIF_L3>;
			dual_sync_video_fhd_int = <DVFS_INT_L3>;
			dual_sync_video_fhd_hpg = <1>;

			dual_sync_video_fhd_capture_int_cam = <DVFS_INT_CAM_L3>;
			dual_sync_video_fhd_capture_tnr = <DVFS_TNR_L3>;
			dual_sync_video_fhd_capture_cam = <DVFS_CAM_L1>;	/* OTF */
			dual_sync_video_fhd_capture_mif = <DVFS_MIF_L0>;
			dual_sync_video_fhd_capture_int = <DVFS_INT_L0>;
			dual_sync_video_fhd_capture_hpg = <1>;

			dual_sync_video_uhd_int_cam = <DVFS_INT_CAM_L3>;
			dual_sync_video_uhd_tnr = <DVFS_TNR_L3>;
			dual_sync_video_uhd_cam = <DVFS_CAM_L1>;	/* OTF */
			dual_sync_video_uhd_mif = <DVFS_MIF_L3>;
			dual_sync_video_uhd_int = <DVFS_INT_L0>;
			dual_sync_video_uhd_hpg = <1>;

			dual_sync_video_uhd_capture_int_cam = <DVFS_INT_CAM_L3>;
			dual_sync_video_uhd_capture_tnr = <DVFS_TNR_L3>;
			dual_sync_video_uhd_capture_cam = <DVFS_CAM_L1>;	/* OTF */
			dual_sync_video_uhd_capture_mif = <DVFS_MIF_L0>;
			dual_sync_video_uhd_capture_int = <DVFS_INT_L0>;
			dual_sync_video_uhd_capture_hpg = <1>;

			secure_front_int_cam = <DVFS_INT_CAM_L5>;
			secure_front_tnr = <DVFS_TNR_L5>;
			secure_front_cam = <DVFS_CAM_L4>;
			secure_front_mif = <DVFS_MIF_L3>;
			secure_front_int = <DVFS_INT_L3>;
			secure_front_hpg = <1>;

			pip_preview_int_cam = <DVFS_INT_CAM_L3>;
			pip_preview_tnr = <DVFS_TNR_L3>;
			pip_preview_cam = <DVFS_CAM_L1>;
			pip_preview_mif = <DVFS_MIF_L1>;
			pip_preview_int = <DVFS_INT_L0>;
			pip_preview_hpg = <1>;

			pip_capture_int_cam = <DVFS_INT_CAM_L3>;
			pip_capture_tnr = <DVFS_TNR_L3>;
			pip_capture_cam = <DVFS_CAM_L1>;
			pip_capture_mif = <DVFS_MIF_L1>;
			pip_capture_int = <DVFS_INT_L0>;
			pip_capture_hpg = <1>;

			pip_video_int_cam = <DVFS_INT_CAM_L3>;
			pip_video_tnr = <DVFS_TNR_L3>;
			pip_video_cam = <DVFS_CAM_L1>;
			pip_video_mif = <DVFS_MIF_L1>;
			pip_video_int = <DVFS_INT_L0>;
			pip_video_hpg = <1>;

			pip_video_capture_int_cam = <DVFS_INT_CAM_L3>;
			pip_video_capture_tnr = <DVFS_TNR_L3>;
			pip_video_capture_cam = <DVFS_CAM_L1>;
			pip_video_capture_mif = <DVFS_MIF_L1>;
			pip_video_capture_int = <DVFS_INT_L0>;
			pip_video_capture_hpg = <1>;

			preview_high_speed_fps_int_cam = <DVFS_INT_CAM_L1>;
			preview_high_speed_fps_tnr = <DVFS_TNR_L1>;
			preview_high_speed_fps_cam = <DVFS_CAM_L1>;		/* VOTF */
			preview_high_speed_fps_mif = <DVFS_MIF_L1>;
			preview_high_speed_fps_int = <DVFS_INT_L1>;
			preview_high_speed_fps_hpg = <1>;

			video_high_speed_60fps_int_cam = <DVFS_INT_CAM_L5>;
			video_high_speed_60fps_tnr = <DVFS_TNR_L5>;
			video_high_speed_60fps_cam = <DVFS_CAM_L1>;		/* OTF */
			video_high_speed_60fps_mif = <DVFS_MIF_L3>;		/* video snapshot */
			video_high_speed_60fps_int = <DVFS_INT_L3>;
			video_high_speed_60fps_hpg = <1>;

			video_high_speed_60fps_pro_int_cam = <DVFS_INT_CAM_L5>;
			video_high_speed_60fps_pro_tnr = <DVFS_TNR_L5>;
			video_high_speed_60fps_pro_cam = <DVFS_CAM_L1>;		/* OTF */
			video_high_speed_60fps_pro_mif = <DVFS_MIF_L5>;		/* Y2 MIF(L5), C2 MIF(L3) */
			video_high_speed_60fps_pro_int = <DVFS_INT_L3>;
			video_high_speed_60fps_pro_hpg = <1>;

			video_high_speed_120fps_int_cam = <DVFS_INT_CAM_L3>;
			video_high_speed_120fps_tnr = <DVFS_TNR_L3>;
			video_high_speed_120fps_cam = <DVFS_CAM_L1>;	/* VOTF */
			video_high_speed_120fps_mif = <DVFS_MIF_L3>;
			video_high_speed_120fps_int = <DVFS_INT_L2>;
			video_high_speed_120fps_hpg = <1>;

			video_high_speed_120fps_pro_int_cam = <DVFS_INT_CAM_L3>;
			video_high_speed_120fps_pro_tnr = <DVFS_TNR_L3>;
			video_high_speed_120fps_pro_cam = <DVFS_CAM_L1>;	/* VOTF */
			video_high_speed_120fps_pro_mif = <DVFS_MIF_L4>;
			video_high_speed_120fps_pro_int = <DVFS_INT_L2>;
			video_high_speed_120fps_pro_hpg = <1>;

			video_high_speed_240fps_int_cam = <DVFS_INT_CAM_L3>;
			video_high_speed_240fps_tnr = <DVFS_TNR_L3>;
			video_high_speed_240fps_cam = <DVFS_CAM_L1>;	/* VOTF */
			video_high_speed_240fps_mif = <DVFS_MIF_L3>;
			video_high_speed_240fps_int = <DVFS_INT_L2>;
			video_high_speed_240fps_hpg = <1>;

			video_high_speed_480fps_int_cam = <DVFS_INT_CAM_L1>;
			video_high_speed_480fps_tnr = <DVFS_TNR_L1>;
			video_high_speed_480fps_cam = <DVFS_CAM_L1>;	/* VOTF */
			video_high_speed_480fps_mif = <DVFS_MIF_L3>;
			video_high_speed_480fps_int = <DVFS_INT_L2>;
			video_high_speed_480fps_hpg = <1>;

			video_high_speed_960fps_int_cam = <DVFS_INT_CAM_L1>;
			video_high_speed_960fps_tnr = <DVFS_TNR_L1>;
			video_high_speed_960fps_cam = <DVFS_CAM_L1>;	/* VOTF */
			video_high_speed_960fps_mif = <DVFS_MIF_L3>;
			video_high_speed_960fps_int = <DVFS_INT_L2>;
			video_high_speed_960fps_hpg = <1>;

			video_high_speed_dualfps_int_cam = <DVFS_INT_CAM_L3>;
			video_high_speed_dualfps_tnr = <DVFS_TNR_L3>;
			video_high_speed_dualfps_cam = <DVFS_CAM_L1>;	/* VOTF */
			video_high_speed_dualfps_mif = <DVFS_MIF_L3>;
			video_high_speed_dualfps_int = <DVFS_INT_L2>;
			video_high_speed_dualfps_hpg = <6>;

			video_high_speed_60fps_capture_int_cam = <DVFS_INT_CAM_L3>;
			video_high_speed_60fps_capture_tnr = <DVFS_TNR_L3>;
			video_high_speed_60fps_capture_cam = <DVFS_CAM_L1>;	/* OTF */
			video_high_speed_60fps_capture_mif = <DVFS_MIF_L0>;
			video_high_speed_60fps_capture_int = <DVFS_INT_L2>;
			video_high_speed_60fps_capture_hpg = <1>;

			ext_rear_int_cam = <DVFS_INT_CAM_L5>;
			ext_rear_tnr = <DVFS_TNR_L5>;
			ext_rear_cam = <DVFS_CAM_L4>;
			ext_rear_mif = <DVFS_MIF_L3>;
			ext_rear_int = <DVFS_INT_L3>;
			ext_rear_hpg = <1>;

			ext_secure_int_cam = <DVFS_INT_CAM_L5>;
			ext_secure_tnr = <DVFS_TNR_L5>;
			ext_secure_cam = <DVFS_CAM_L4>;
			ext_secure_mif = <DVFS_MIF_L3>;
			ext_secure_int = <DVFS_INT_L3>;
			ext_secure_hpg = <1>;

			thermal_8k_int_cam = <0>;
			thermal_8k_tnr = <0>;
			thermal_8k_cam = <0>;
			thermal_8k_mif = <DVFS_MIF_L2>;
			thermal_8k_int = <0>;
			thermal_8k_hpg = <1>;

			max_int_cam = <DVFS_INT_CAM_L3>;
			max_tnr = <DVFS_TNR_L3>;
			max_cam = <DVFS_CAM_L0>;
			max_mif = <DVFS_MIF_L0>;
			max_int = <DVFS_INT_L0>;
			max_hpg = <1>;
		};
	};
};

/* Flicker */
&pinctrl_0 {
	als_irq: als_irq-irq {
		samsung,pins = "gpa2-7";
		samsung,pin-function = <0>;
		samsung,pin-con-pdn = <2>;
		samsung,pin-pud-pdn = <0>;
	};

	als_irqsleep: als_irqsleep {
		samsung,pins = "gpa2-7";
		samsung,pin-function = <0>;
		samsung,pin-pud = <1>;
	};

	als_irqidle: als_irqidle {
		samsung,pins = "gpa2-7";
		samsung,pin-function = <0xf>;
		samsung,pin-pud = <0>;
		samsung,pin-drv = <3>;
	};
};

&pinctrl_4 {
	als_torch_out: als-torch-out {
		samsung,pins = "gpp4-4";
		samsung,pin-function = <1>;
		samsung,pin-pud = <0>;
	};

	als_torch_pwm: als-torch-pwm {
		samsung,pins = "gpp4-4";
		samsung,pin-function = <2>;
		samsung,pin-pud = <0>;
	};
};

&hsi2c_25 {
	gpios = <&gpp8 2 0 &gpp8 3 0>;
	status = "okay";
	clock-frequency = <400000>;

	als_rear@29 {
		compatible = "ams,tcs3407";
		reg = <0x29>;
		interrupt-parent = <&gpa2>;
		interrupts = <7 0 0>;
		pinctrl-names = "default", "sleep", "idle", "torch_out", "torch_pwm";
		pinctrl-0 = <&als_irq &flash_init &torch_init>;
		pinctrl-1 = <&als_irqsleep &sensor_reset_sleep &tof_reset_sleep &hsi2c45_bus_sleep>;
		pinctrl-2 = <&als_irqidle>;
		pinctrl-3 = <&als_torch_out>;
		pinctrl-4 = <&als_torch_pwm>;
		als_rear,int-gpio = <&gpa2 7 0>;
		als_rear,led_en-gpio = <&gpp4 4 0>;  /* CAM_TORCH_EN */
		als_rear,vdd_1p8 = "VDD_FLICKER_1P8";	/* LDO25M */
		als_rear,i2c_1p8 = "VDD_NFC_1P8"; 		/* LDO22M */
		als_rear,gain_max = <0xbc>;
		als_rear,ir_spec = <0 500000 0 500000>;
		als_rear,clear_spec = <0 500000 0 500000>;
		als_rear,icratio_spec = <0 10000 0 10000>;
		/*pwms = <&sec_pwm 1 5000000 0>; */ /*  PWM channel, period(ns),  polarity */
		pwm-names = "cam_torch_en";
	};
};

&lic_lut_origin {
	#define LIC_MODE_DYNAMIC	(0)
	#define LIC_MODE_STATIC		(1)
	#define LIC_PATH_OTF		(0)
	#define LIC_PATH_DMA		(1)
	#define LIC_TOTAL_SIZE		(3584)

	lic_mode_default = <LIC_MODE_STATIC>;

	/*
	 * When DYNAMIC mode is selected, param means enable limitation for DMA path.
	 * Example:
	 * @ mode = <LIC_MODE_DYNAMIC>;
	 * @ param0 = <LIC_PATH_OTF>;
	 * @ param1 = <LIC_PATH_DMA>;
	 * @ param2 = <LIC_PATH_OTF>;
	 *
	 * When STATIC mode is selected, param means buffer size for each context.
	 * Example:
	 * @ mode = <LIC_MODE_STAIC>;
	 * @ param0 = <3584>;
	 * @ param1 = <3583>;
	 * @ param2 = <1>;
	 *
	 * The lic_scen0 is not abailable. If the index of LUT is "0", the selection is skipped.
	 */
	lic_scen0 { /* Reserved */
		mode = <0>;
		param0 = <0>;
		param1 = <0>;
		param2 = <0>;
	};

	lic_scen1 { /* rear 120fps fast AE */
		mode = <LIC_MODE_STATIC>;
		param0 = <1792>;
		param1 = <1792>;
		param2 = <0>;
	};
};
